VERSION ""

NS_ :

BS_:
BU_: Manager30 Battery_Sensor Redvision_1 Redvision_2 TVMS_Rouge TVMS_1280 Config_Tool

CM_ "Current/SOC decode v27. Long-log cleanup: source Manager30 and Battery Sensor currents are 32-bit little-endian values centred at exactly 1,000,000. Formula is raw/1000 - 1000. Redvision display copies are 16-bit values centred at exactly 10,000. Formula is raw/10 - 1000.";

CM_ BU_ Manager30 "Source address 0x01.";
CM_ BU_ Battery_Sensor "Source address 0x08.";
CM_ BU_ Redvision_1 "Source address 0x20.";
CM_ BU_ Redvision_2 "Source address 0x21.";

BO_ 2213677569 PGN_03F20A_Manager30_OutputCurrent: 8 Manager30
 SG_ Manager_Output_Current_A : 0|32@1+ (0.001,-1000) [-300|100] "A" Vector__XXX
 SG_ Manager_Battery_Voltage : 32|16@1+ (0.001,0) [0|20] "V" Vector__XXX

CM_ BO_ 2213677569 "Raw CAN ID 0x03F20A01, PGN 0x03F20A, SA 0x01 Manager30.";
CM_ SG_ 2213677569 Manager_Output_Current_A "Primary Manager30 output current. D1-D4 little-endian uint32. Clean formula: raw/1000 - 1000. Zero current raw = 1000000 = 0x000F4240, bytes 40 42 0F 00.";

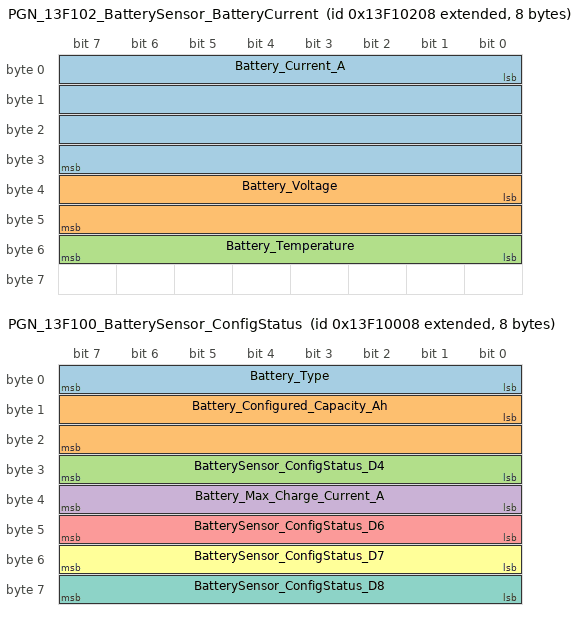
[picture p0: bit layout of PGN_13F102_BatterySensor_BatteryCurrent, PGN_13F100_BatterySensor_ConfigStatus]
BO_ 2482045448 PGN_13F102_BatterySensor_BatteryCurrent: 8 Battery_Sensor
 SG_ Battery_Current_A : 0|32@1+ (0.001,-1000) [-300|100] "A" Vector__XXX
 SG_ Battery_Voltage : 32|16@1+ (0.001,0) [0|20] "V" Vector__XXX
 SG_ Battery_Temperature : 48|8@1+ (1,-60) [-60|195] "degC" Vector__XXX

CM_ BO_ 2482045448 "Raw CAN ID 0x13F10208, PGN 0x13F102, SA 0x08 Battery_Sensor.";
CM_ SG_ 2482045448 Battery_Current_A "Primary battery current. D1-D4 little-endian uint32. Clean formula: raw/1000 - 1000. Positive = charging into batteries; negative = discharging from batteries. Zero current raw = 1000000 = 0x000F4240.";

BO_ 2482045960 PGN_13F104_BatterySensor_SOC: 8 Battery_Sensor
 SG_ Battery_SOC_Percent : 0|8@1+ (1,0) [0|100] "%" Vector__XXX

CM_ BO_ 2482045960 "Raw CAN ID 0x13F10408, PGN 0x13F104, SA 0x08 Battery_Sensor.";
CM_ SG_ 2482045960 Battery_SOC_Percent "Battery state of charge. D1 raw percent. Confirmed 99to97.csv: 0x63 -> 99%, 0x62 -> 98%, 0x61 -> 97%.";

BO_ 2482044936 PGN_13F100_BatterySensor_ConfigStatus: 8 Battery_Sensor
 SG_ Battery_Type : 0|8@1+ (1,0) [0|4] "type" Vector__XXX
 SG_ Battery_Configured_Capacity_Ah : 8|16@1+ (1,0) [0|1000] "Ah" Vector__XXX
 SG_ BatterySensor_ConfigStatus_D4 : 24|8@1+ (1,0) [0|255] "raw" Vector__XXX
 SG_ Battery_Max_Charge_Current_A : 32|8@1+ (1,0) [0|100] "A" Vector__XXX
 SG_ BatterySensor_ConfigStatus_D6 : 40|8@1+ (1,0) [0|255] "raw" Vector__XXX
 SG_ BatterySensor_ConfigStatus_D7 : 48|8@1+ (1,0) [0|255] "raw" Vector__XXX
 SG_ BatterySensor_ConfigStatus_D8 : 56|8@1+ (1,0) [0|255] "raw" Vector__XXX

CM_ BO_ 2482044936 "CONFIRMED_CORRECT_DO_NOT_EDIT: Battery Sensor config/status echo. Raw CAN ID 0x13F10008, private DGN 0x1F100, SA 0x08. D1 reports battery type, D2-D3 little-endian reports configured capacity Ah, D5 reports max charge current A.";
CM_ SG_ 2482044936 Battery_Type "D1 battery type. Confirmed from battery type change 5 times.csv: 0=Gel, 1=AGM, 2=LeadAcid, 3=Calcium, 4=Lithium.";
CM_ SG_ 2482044936 Battery_Configured_Capacity_Ah "D2-D3 little-endian unsigned Ah. Confirmed values: C2 01 = 450 Ah, 90 01 = 400 Ah, 5E 01 = 350 Ah.";
CM_ SG_ 2482044936 Battery_Max_Charge_Current_A "D5 raw amps. Confirmed from max charge current 20a - 15 - 20 -30.csv after correction: values follow 20 A, 14 A, 10 A, 30 A.";

BO_ 2399144186 BatterySensor_Config_Write_FromTool: 8 Config_Tool
 SG_ BatteryConfigWrite_Command M : 0|8@1+ (1,0) [0|255] "raw" Vector__XXX
 SG_ BatteryConfigWrite_D2 : 8|8@1+ (1,0) [0|255] "raw" Vector__XXX
 SG_ BatteryConfigWrite_Item : 16|8@1+ (1,0) [0|255] "raw" Vector__XXX
 SG_ BatteryConfigWrite_D4 : 24|8@1+ (1,0) [0|255] "raw" Vector__XXX
 SG_ BatteryConfigWrite_BatteryType m17 : 32|16@1+ (1,0) [0|4] "type" Vector__XXX
 SG_ BatteryConfigWrite_Capacity_Ah m18 : 32|16@1+ (1,0) [0|1000] "Ah" Vector__XXX
 SG_ BatteryConfigWrite_MaxChargeCurrent_A m20 : 32|16@1+ (1,0) [0|100] "A" Vector__XXX
 SG_ BatteryConfigWrite_SOCCalibrationTarget_Percent m21 : 32|16@1+ (1,0) [0|100] "%" Vector__XXX
 SG_ BatteryConfigWrite_LowSOCAlarm_Percent m65 : 32|16@1+ (1,0) [0|100] "%" Vector__XXX
 SG_ BatteryConfigWrite_LowVoltageAlarm_V m66 : 32|16@1+ (0.001,0) [0|60] "V" Vector__XXX
 SG_ BatteryConfigWrite_D7 : 48|8@1+ (1,0) [0|255] "raw" Vector__XXX
 SG_ BatteryConfigWrite_D8 : 56|8@1+ (1,0) [0|255] "raw" Vector__XXX

CM_ BO_ 2399144186 "CONFIRMED_CORRECT_DO_NOT_EDIT: Battery config write from source 0xFA to Battery_Sensor destination 0x08. Raw CAN ID 0x0F0008FA. D1 is command/mux; D1=0x11 writes battery type, D1=0x12 writes configured capacity Ah, D1=0x14 writes max charge current A, D1=0x15 calibrates/sets SOC target %, D1=0x41 writes low SOC alarm %, D1=0x42 writes low voltage alarm V.";
CM_ SG_ 2399144186 BatteryConfigWrite_Command "D1 command/mux. 0x11 = battery type, 0x12 = configured capacity, 0x14 = max charge current, 0x15 = SOC calibration target, 0x41 = low SOC alarm, 0x42 = low voltage alarm.";
CM_ SG_ 2399144186 BatteryConfigWrite_Item "D3 observed 0x03 for these battery config writes.";
CM_ SG_ 2399144186 BatteryConfigWrite_Capacity_Ah "D5-D6 little-endian unsigned Ah. Controlled sequence captured: 450 Ah, 400 Ah, 350 Ah, 400 Ah.";
CM_ SG_ 2399144186 BatteryConfigWrite_BatteryType "D5-D6 little-endian battery type. Confirmed from battery type change 5 times.csv sequence: 0=Gel, 1=AGM, 2=LeadAcid, 3=Calcium, 4=Lithium.";
CM_ SG_ 2399144186 BatteryConfigWrite_MaxChargeCurrent_A "D5-D6 little-endian unsigned A. Controlled sequence captured and corrected by user: 20 A, 14 A, 10 A, 30 A.";
CM_ SG_ 2399144186 BatteryConfigWrite_SOCCalibrationTarget_Percent "D5-D6 little-endian unsigned percent. calibrate battery start of charge full 5 times.csv captured five repeats of D1=0x15, D5-D6=0x0064, calibrating/setting battery SOC to 100%.";
CM_ SG_ 2399144186 BatteryConfigWrite_LowSOCAlarm_Percent "D5-D6 little-endian unsigned percent. Confirmed sequence from more battery config.csv: 10%, 15%, 20%, 30%.";
CM_ SG_ 2399144186 BatteryConfigWrite_LowVoltageAlarm_V "D5-D6 little-endian millivolts, scale 0.001 V/count. Confirmed sequence from more battery config.csv: 10.0 V, 11.0 V, 11.5 V, 12.0 V.";
VAL_ 2482044936 Battery_Type 0 "Gel" 1 "AGM" 2 "LeadAcid" 3 "Calcium" 4 "Lithium" ;
VAL_ 2399144186 BatteryConfigWrite_Command 17 "BatteryType" 18 "ConfiguredCapacity" 20 "MaxChargeCurrent" 21 "SOCCalibrationTarget" 65 "LowSOCAlarm" 66 "LowVoltageAlarm" ;
VAL_ 2399144186 BatteryConfigWrite_BatteryType 0 "Gel" 1 "AGM" 2 "LeadAcid" 3 "Calcium" 4 "Lithium" ;

BO_ 2399207200 Redvision1_Config_Setting_Broadcast: 8 Redvision_1
 SG_ RedvisionConfigBroadcast_Command M : 0|8@1+ (1,0) [0|255] "raw" Vector__XXX
 SG_ RedvisionConfigBroadcast_D2 : 8|8@1+ (1,0) [0|255] "raw" Vector__XXX
 SG_ RedvisionConfigBroadcast_D3 : 16|8@1+ (1,0) [0|255] "raw" Vector__XXX
 SG_ RedvisionConfigBroadcast_D4 : 24|8@1+ (1,0) [0|255] "raw" Vector__XXX
 SG_ RedvisionConfigBroadcast_BatteryType m17 : 32|16@1+ (1,0) [0|4] "type" Vector__XXX
 SG_ RedvisionConfigBroadcast_Capacity_Ah m18 : 32|16@1+ (1,0) [0|1000] "Ah" Vector__XXX
 SG_ RedvisionConfigBroadcast_MaxChargeCurrent_A m20 : 32|16@1+ (1,0) [0|100] "A" Vector__XXX
 SG_ RedvisionConfigBroadcast_LowSOCAlarm_Percent m65 : 32|16@1+ (1,0) [0|100] "%" Vector__XXX
 SG_ RedvisionConfigBroadcast_LowVoltageAlarm_V m66 : 32|16@1+ (0.001,0) [0|60] "V" Vector__XXX
 SG_ RedvisionConfigBroadcast_ChargingMode m67 : 32|8@1+ (1,0) [0|1] "mode" Vector__XXX
 SG_ RedvisionConfigBroadcast_ChargeCycleRequest_Candidate m77 : 32|8@1+ (1,0) [0|1] "request" Vector__XXX
 SG_ RedvisionConfigBroadcast_VehicleInputTrigger m104 : 32|16@1+ (1,0) [0|5] "trigger" Vector__XXX
 SG_ RedvisionConfigBroadcast_D7 : 48|8@1+ (1,0) [0|255] "raw" Vector__XXX
 SG_ RedvisionConfigBroadcast_D8 : 56|8@1+ (1,0) [0|255] "raw" Vector__XXX

CM_ BO_ 2399207200 "CONFIRMED_CORRECT_DO_NOT_EDIT: Redvision Display 1 local setting-change broadcast. Raw CAN ID 0x0F00FF20, source 0x20. Payload pattern <setting> 00 FF FF <value little-endian> 00 00. battery changes from redvision.csv shows the same setting IDs and value encoding as Bluetooth/config-tool changes.";
CM_ SG_ 2399207200 RedvisionConfigBroadcast_Command "D1 setting/mux. 0x11 = battery type, 0x12 = configured capacity, 0x14 = max charge current, 0x41 = low SOC alarm, 0x42 = low voltage alarm, 0x43 = Manager30 charging mode, 0x4D = charge-cycle/stage request candidate, 0x68 = vehicle input trigger.";
CM_ SG_ 2399207200 RedvisionConfigBroadcast_D3 "D3 observed 0xFF for these Redvision setting broadcasts.";
CM_ SG_ 2399207200 RedvisionConfigBroadcast_D4 "D4 observed 0xFF for these Redvision setting broadcasts.";
CM_ SG_ 2399207200 RedvisionConfigBroadcast_BatteryType "D5-D6 little-endian battery type. Confirmed examples: 2=LeadAcid, 0=Gel, 4=Lithium.";
CM_ SG_ 2399207200 RedvisionConfigBroadcast_Capacity_Ah "D5-D6 little-endian unsigned Ah. Confirmed examples: 0x0177=375 Ah, 0x0154=340 Ah, 0x0190=400 Ah.";
CM_ SG_ 2399207200 RedvisionConfigBroadcast_MaxChargeCurrent_A "D5-D6 little-endian unsigned A. Confirmed example: 0x001E=30 A.";
CM_ SG_ 2399207200 RedvisionConfigBroadcast_LowSOCAlarm_Percent "D5-D6 little-endian unsigned percent. Confirmed example: 0x001E=30%.";
CM_ SG_ 2399207200 RedvisionConfigBroadcast_LowVoltageAlarm_V "D5-D6 little-endian millivolts, scale 0.001 V/count. Confirmed example: 0x2EE0=12.0 V.";
CM_ SG_ 2399207200 RedvisionConfigBroadcast_ChargingMode "CONFIRMED_CORRECT_DO_NOT_EDIT: D1=0x43 Manager30 charging mode command. D5=0x00 Touring, D5=0x01 Storage. Observed RedVision source 0x20 sends 43 00 FF FF <mode> 00 00 00.";
CM_ SG_ 2399207200 RedvisionConfigBroadcast_ChargeCycleRequest_Candidate "PARTLY_CONFIRMED: D1=0x4D charge-cycle/stage request candidate. Observed 4D 00 FF FF 01 00 00 00 before later Float->Boost transition, but it did not immediately change live stage status.";
CM_ SG_ 2399207200 RedvisionConfigBroadcast_VehicleInputTrigger "D5-D6 little-endian trigger value. Confirmed examples: 0=Auto, 1=12V, 3=Ignition.";
CM_ SG_ 2399207200 RedvisionConfigBroadcast_D7 "D7 observed 0x00 for these Redvision setting broadcasts.";
CM_ SG_ 2399207200 RedvisionConfigBroadcast_D8 "D8 observed 0x00 for these Redvision setting broadcasts.";
VAL_ 2399207200 RedvisionConfigBroadcast_Command 17 "BatteryType" 18 "ConfiguredCapacity" 20 "MaxChargeCurrent" 65 "LowSOCAlarm" 66 "LowVoltageAlarm" 67 "ChargingMode" 77 "ChargeCycleRequest_Candidate" 104 "VehicleInputTrigger" ;
VAL_ 2399207200 RedvisionConfigBroadcast_BatteryType 0 "Gel" 1 "AGM" 2 "LeadAcid" 3 "Calcium" 4 "Lithium" ;
VAL_ 2399207200 RedvisionConfigBroadcast_ChargingMode 0 "Touring" 1 "Storage" ;
VAL_ 2399207200 RedvisionConfigBroadcast_ChargeCycleRequest_Candidate 1 "RequestBoostOrRestartCycle" ;
VAL_ 2399207200 RedvisionConfigBroadcast_VehicleInputTrigger 0 "Auto" 1 "12V" 2 "24V" 3 "Ignition" 5 "On" ;

BO_ 2482143264 PGN_13F280_Redvision1_CurrentDisplay: 8 Redvision_1
 SG_ RV1_Battery_Current_Display_A : 0|16@1+ (0.1,-1000) [-300|100] "A" Vector__XXX
 SG_ RV1_Device_Current_Display_A : 32|16@1+ (0.1,-1000) [0|300] "A" Vector__XXX

CM_ BO_ 2482143264 "Raw CAN ID 0x13F28020, PGN 0x13F280, SA 0x20 Redvision_1. Redvision display/rebroadcast current values.";
CM_ SG_ 2482143264 RV1_Battery_Current_Display_A "Redvision_1 displayed battery current. D1-D2 little-endian uint16. Clean formula: raw/10 - 1000. Zero current raw = 10000 = 0x2710.";
CM_ SG_ 2482143264 RV1_Device_Current_Display_A "Redvision_1 displayed device/load current. D5-D6 little-endian uint16. Clean formula: raw/10 - 1000. Zero current raw = 10000 = 0x2710.";

BO_ 2482143777 PGN_13F282_Redvision2_CurrentDisplay: 8 Redvision_2
 SG_ RV2_Manager_Output_Current_Display_A : 48|16@1+ (0.1,-1000) [-50|100] "A" Vector__XXX

CM_ BO_ 2482143777 "Raw CAN ID 0x13F28221, PGN 0x13F282, SA 0x21 Redvision_2. Redvision display/rebroadcast Manager30 output current.";
CM_ SG_ 2482143777 RV2_Manager_Output_Current_Display_A "Redvision_2 displayed Manager30 output current. D7-D8 little-endian uint16. Clean formula: raw/10 - 1000. Zero current raw = 10000 = 0x2710.";

CM_ "Derived source-node device/load current: Device_Current_A = Manager_Output_Current_A - Battery_Current_A.";
CM_ "Battery_Current_A sign convention: positive means charging into batteries; negative means battery discharge.";
CM_ "Long-log validation: Manager30 0x03F20A01 D1-D4 raw 0x000F4240 decodes 0 A; raw around 1030700 decodes about 30.7 A.";
CM_ "Long-log validation: Battery Sensor 0x13F10208 D1-D4 decodes from about -212 A to +30 A and tracks Redvision_1 battery display.";
CM_ "Redvision validation: display currents remain centred on 10000 with 0.1 A/count.";

BO_ 2617049648 PGN_1BFD02_TVMSRouge_WaterTankLevels: 8 TVMS_Rouge
 SG_ WaterTank_MUX M : 0|8@1+ (1,0) [0|255] "" Vector__XXX
 SG_ WaterTank1_Percent m9 : 8|8@1+ (1,0) [0|100] "%" Vector__XXX
 SG_ WaterTank2_Percent m9 : 16|8@1+ (1,0) [0|100] "%" Vector__XXX
 SG_ TVMSRouge_Input_Voltage m22 : 8|16@1+ (0.001,0) [0|65.535] "V" Vector__XXX
 SG_ TVMSRouge_Input_Current_A_Candidate m22 : 16|8@1+ (0.1,0) [0|25.5] "A" Vector__XXX

CM_ BO_ 2617049648 "Confirmed TVMS_Rouge water tank levels. Raw CAN ID 0x1BFD0230, PGN 0xFD02, source address 0x30.";
CM_ SG_ 2617049648 WaterTank_MUX "D1 message type/mux. 0x09 = water tank levels. 0x16 = live input voltage and current.";
CM_ SG_ 2617049648 WaterTank1_Percent "D2 = Tank 1 level percent. 0x00 = 0%, 0x64 = 100%. Scale: raw percent.";
CM_ SG_ 2617049648 WaterTank2_Percent "D3 = Tank 2 level percent. 0x00 = 0%, 0x64 = 100%. Scale: raw percent.";
CM_ SG_ 2617049648 TVMSRouge_Input_Voltage "CONFIRMED_CORRECT_DO_NOT_EDIT: MUX 0x16, D2-D3 little-endian uint16 millivolts. Live input voltage. ESPHome: data[1]|(data[2]<<8) / 1000.0.";
CM_ SG_ 2617049648 TVMSRouge_Input_Current_A_Candidate "DECODE_WRONG_PENDING_RETEST: Label pages identify item 0x17 as Input Current, but 0x1BFD0230 D1=0x16 D3 is the high byte of the confirmed D2-D3 input-voltage millivolt field. Do not publish D3/10 A as current. Find the real current page, likely item/mux 0x17 or another frame, with controlled load-current testing.";
VAL_ 2617049648 WaterTank_MUX 9 "WaterTankLevels" 22 "InputVoltageCurrentCandidates";

CM_

BA_ "Decode_Status"

CM_ "v30 update: added confirmed TVMS_1280 Tank1 level on 0x1BFD0224 MUX 0x14 D4, raw percent.";

CM_ "v31 TVMS1280 water 1-6 review: only one clean raw 25%/0% tank-level field was found in the uploaded log: raw CAN ID 0x1BFD0224, MUX 0x14, D4 = TVMS1280_Tank1_Percent. No separate confirmed 25/0 raw percent fields for TVMS1280 tanks 2-6 were visible in this capture, so they were not added as confirmed signals.";
CM_ "TVMS1280 Tank1 validation from TVMS1280 water 1-6.csv: log starts with Tank1 at 25%, later D4 changes to 0%, and ends with Tank1 back at 25%.";

CM_ "v32 TVMS1280 Tank2 review: 1280 tank 2 100-0.csv was inspected. No source address 0x24 field showed a clean 100% to 0% raw-percent change, so TVMS1280_Tank2_Percent was not added as a confirmed signal.";
CM_ "v32 observed 0x24 frames: 0x1BFD0224 cycles mux 0x11/0x14/0x17/0x1A; mux 0x14 D4, previously confirmed Tank1, remained 0 in this capture. 0x1BFD0024 and other source 0x24 frames were static/status-like and did not carry a 100 to 0 percent value.";

CM_

BA_ "Decode_Status"

CM_ "v33 update: TVMS1280 Tank2 confirmed on raw CAN ID 0x1BFD0224, mux 0x14, D6, raw percent.";

CM_
 0x00=0%, 0x64=100%.";

BA_ "Decode_Status" 


CM_ "v35 update: mux 0x1A D2 renamed from TVMS1280_Tank5_Percent to TVMS1280_Tank6_Percent per confirmed physical mapping.";
CM_ "v53 update: Added TVMS Rouge Input Current candidate. Superseded by later review: D3 in 0x1BFD0230 D1=0x16 belongs to the confirmed D2-D3 voltage field, so D3/10 A must not be used as current.";

BO_ 2617049636 PGN_1BFD02_TVMS1280_TempTankStatus: 8 TVMS_1280
 SG_ TVMS1280_Status_MUX M : 0|8@1+ (1,0) [0|255] "" Vector__XXX
 SG_ TVMS1280_Temp1_C m20 : 8|8@1+ (1,-100) [-100|155] "degC" Vector__XXX
 SG_ TVMS1280_Tank1_Percent m20 : 24|8@1+ (1,0) [0|100] "%" Vector__XXX
 SG_ TVMS1280_Tank2_Percent m20 : 40|8@1+ (1,0) [0|100] "%" Vector__XXX
 SG_ TVMS1280_Tank3_Percent m23 : 8|8@1+ (1,0) [0|100] "%" Vector__XXX
 SG_ TVMS1280_Tank4_Percent m23 : 24|8@1+ (1,0) [0|100] "%" Vector__XXX
 SG_ TVMS1280_Tank5_Percent m23 : 40|8@1+ (1,0) [0|100] "%" Vector__XXX
 SG_ TVMS1280_Tank6_Percent m26 : 8|8@1+ (1,0) [0|100] "%" Vector__XXX
 SG_ TVMS1280_Temp2_C m17 : 40|8@1+ (1,-100) [-100|155] "degC" Vector__XXX
 SG_ TVMS1280_Voltage_Input1 m17 : 8|16@1+ (0.001,0) [0|65.535] "V" Vector__XXX
 SG_ TVMS1280_Voltage_Input2 m17 : 24|16@1+ (0.001,0) [0|65.535] "V" Vector__XXX

CM_ BO_ 2617049636 "Confirmed TVMS_1280 temp/tank status. Raw CAN ID 0x1BFD0224, PGN 0xFD02, source address 0x24. Also a candidate frame to watch for the 3 currently unused TVMS1280 digital inputs, but no digital-input decode is confirmed.";
CM_ SG_ 2617049636 TVMS1280_Status_MUX "D1 multiplexor. 0x11 contains Voltage Input 1, Voltage Input 2 and Temp2. 0x14 contains Temp1, Tank1 and Tank2. 0x17 contains Tank3, Tank4 and Tank5. 0x1A contains Tank6.";
CM_ SG_ 2617049636 TVMS1280_Temp1_C "MUX 0x14, D2. Temperature formula raw - 100.";
CM_ SG_ 2617049636 TVMS1280_Tank1_Percent "MUX 0x14, D4. Raw percent.";
CM_ SG_ 2617049636 TVMS1280_Tank2_Percent "MUX 0x14, D6. Raw percent.";
CM_ SG_ 2617049636 TVMS1280_Tank3_Percent "MUX 0x17, D2. Raw percent.";
CM_ SG_ 2617049636 TVMS1280_Tank4_Percent "MUX 0x17, D4. Raw percent.";
CM_ SG_ 2617049636 TVMS1280_Tank5_Percent "CONFIRMED_CORRECT_DO_NOT_EDIT: MUX 0x17, D6. Confirmed TVMS1280 Tank 5 percent. Raw value is percent; 0x00=0%, 0x64=100%.";
CM_ SG_ 2617049636 TVMS1280_Tank6_Percent "MUX 0x1A, D2. Raw percent.";
CM_ SG_ 2617049636 TVMS1280_Temp2_C "MUX 0x11, D6. Temperature formula raw - 100.";
CM_ SG_ 2617049636 TVMS1280_Voltage_Input1 "CONFIRMED_CORRECT_DO_NOT_EDIT: MUX 0x11, D2-D3 little-endian uint16 millivolts. Voltage Input 1. Confirmed ~13581-13588 mV (~13.5 V) within 0.1 V of Voltage Input 2 in voltage inputs the same.csv capture. ESPHome: data[1]|(data[2]<<8) / 1000.0.";
CM_ SG_ 2617049636 TVMS1280_Voltage_Input2 "CONFIRMED_CORRECT_DO_NOT_EDIT: MUX 0x11, D4-D5 little-endian uint16 millivolts. Voltage Input 2 (same signal as supply voltage). Confirmed ~13531-13536 mV (~13.5 V) in voltage input 1280 555 36.csv capture. ESPHome: data[3]|(data[4]<<8) / 1000.0.";
VAL_ 2617049636 TVMS1280_Status_MUX 17 "Temp2_SupplyVoltage" 20 "Temp1_Tank1_Tank2" 23 "Tank3_Tank4_Tank5" 26 "Tank6";


CM_ "v36 update: TVMS1280 Tank5 confirmed on raw CAN ID 0x1BFD0224, mux 0x17, D6. Tank5 uses scale 1.25 because 0x50 represents 100% in the tank 5 100-0.csv capture.";

BA_DEF_ BO_ "Decode_Status" STRING ;
BA_DEF_ SG_ "Decode_Status" STRING ;
BA_DEF_DEF_ "Decode_Status" "CONFIRMED_CORRECT_DO_NOT_EDIT";
CM_ "LOCKED_CONFIRMED_DECODE: Every message and signal in this DBC is marked CONFIRMED_CORRECT_DO_NOT_EDIT per user request. Do not change these values unless the user explicitly requests a correction.";
BA_ "Decode_Status" BO_ 2213677569 "CONFIRMED_CORRECT_DO_NOT_EDIT";
BA_ "Decode_Status" SG_ 2213677569 Manager_Output_Current_A "CONFIRMED_CORRECT_DO_NOT_EDIT";
BA_ "Decode_Status" BO_ 2482045448 "CONFIRMED_CORRECT_DO_NOT_EDIT";
BA_ "Decode_Status" SG_ 2482045448 Battery_Current_A "CONFIRMED_CORRECT_DO_NOT_EDIT";
BA_ "Decode_Status" BO_ 2482045960 "CONFIRMED_CORRECT_DO_NOT_EDIT";
BA_ "Decode_Status" SG_ 2482045960 Battery_SOC_Percent "CONFIRMED_CORRECT_DO_NOT_EDIT";
BA_ "Decode_Status" BO_ 2482044936 "CONFIRMED_CORRECT_DO_NOT_EDIT";
BA_ "Decode_Status" SG_ 2482044936 Battery_Type "CONFIRMED_CORRECT_DO_NOT_EDIT";
BA_ "Decode_Status" SG_ 2482044936 Battery_Configured_Capacity_Ah "CONFIRMED_CORRECT_DO_NOT_EDIT";
BA_ "Decode_Status" SG_ 2482044936 BatterySensor_ConfigStatus_D4 "UNCONFIRMED_PENDING_TEST";
BA_ "Decode_Status" SG_ 2482044936 Battery_Max_Charge_Current_A "CONFIRMED_CORRECT_DO_NOT_EDIT";
BA_ "Decode_Status" SG_ 2482044936 BatterySensor_ConfigStatus_D6 "UNCONFIRMED_PENDING_TEST";
BA_ "Decode_Status" SG_ 2482044936 BatterySensor_ConfigStatus_D7 "UNCONFIRMED_PENDING_TEST";
BA_ "Decode_Status" SG_ 2482044936 BatterySensor_ConfigStatus_D8 "UNCONFIRMED_PENDING_TEST";
BA_ "Decode_Status" BO_ 2399144186 "CONFIRMED_CORRECT_DO_NOT_EDIT";
BA_ "Decode_Status" SG_ 2399144186 BatteryConfigWrite_Command "CONFIRMED_CORRECT_DO_NOT_EDIT";
BA_ "Decode_Status" SG_ 2399144186 BatteryConfigWrite_D2 "UNCONFIRMED_PENDING_TEST";
BA_ "Decode_Status" SG_ 2399144186 BatteryConfigWrite_Item "CONFIRMED_CORRECT_DO_NOT_EDIT";
BA_ "Decode_Status" SG_ 2399144186 BatteryConfigWrite_D4 "UNCONFIRMED_PENDING_TEST";
BA_ "Decode_Status" SG_ 2399144186 BatteryConfigWrite_BatteryType "CONFIRMED_CORRECT_DO_NOT_EDIT";
BA_ "Decode_Status" SG_ 2399144186 BatteryConfigWrite_Capacity_Ah "CONFIRMED_CORRECT_DO_NOT_EDIT";
BA_ "Decode_Status" SG_ 2399144186 BatteryConfigWrite_MaxChargeCurrent_A "CONFIRMED_CORRECT_DO_NOT_EDIT";
BA_ "Decode_Status" SG_ 2399144186 BatteryConfigWrite_SOCCalibrationTarget_Percent "CONFIRMED_CORRECT_DO_NOT_EDIT";
BA_ "Decode_Status" SG_ 2399144186 BatteryConfigWrite_LowSOCAlarm_Percent "CONFIRMED_CORRECT_DO_NOT_EDIT";
BA_ "Decode_Status" SG_ 2399144186 BatteryConfigWrite_LowVoltageAlarm_V "CONFIRMED_CORRECT_DO_NOT_EDIT";
BA_ "Decode_Status" SG_ 2399144186 BatteryConfigWrite_D7 "UNCONFIRMED_PENDING_TEST";
BA_ "Decode_Status" SG_ 2399144186 BatteryConfigWrite_D8 "UNCONFIRMED_PENDING_TEST";
BA_ "Decode_Status" BO_ 2399207200 "CONFIRMED_CORRECT_DO_NOT_EDIT";
BA_ "Decode_Status" SG_ 2399207200 RedvisionConfigBroadcast_Command "CONFIRMED_CORRECT_DO_NOT_EDIT";
BA_ "Decode_Status" SG_ 2399207200 RedvisionConfigBroadcast_D2 "UNCONFIRMED_PENDING_TEST";
BA_ "Decode_Status" SG_ 2399207200 RedvisionConfigBroadcast_D3 "CONFIRMED_CORRECT_DO_NOT_EDIT";
BA_ "Decode_Status" SG_ 2399207200 RedvisionConfigBroadcast_D4 "CONFIRMED_CORRECT_DO_NOT_EDIT";
BA_ "Decode_Status" SG_ 2399207200 RedvisionConfigBroadcast_BatteryType "CONFIRMED_CORRECT_DO_NOT_EDIT";
BA_ "Decode_Status" SG_ 2399207200 RedvisionConfigBroadcast_Capacity_Ah "CONFIRMED_CORRECT_DO_NOT_EDIT";
BA_ "Decode_Status" SG_ 2399207200 RedvisionConfigBroadcast_MaxChargeCurrent_A "CONFIRMED_CORRECT_DO_NOT_EDIT";
BA_ "Decode_Status" SG_ 2399207200 RedvisionConfigBroadcast_LowSOCAlarm_Percent "CONFIRMED_CORRECT_DO_NOT_EDIT";
BA_ "Decode_Status" SG_ 2399207200 RedvisionConfigBroadcast_LowVoltageAlarm_V "CONFIRMED_CORRECT_DO_NOT_EDIT";
BA_ "Decode_Status" SG_ 2399207200 RedvisionConfigBroadcast_ChargingMode "CONFIRMED_CORRECT_DO_NOT_EDIT";
BA_ "Decode_Status" SG_ 2399207200 RedvisionConfigBroadcast_ChargeCycleRequest_Candidate "PARTLY_CONFIRMED";
BA_ "Decode_Status" SG_ 2399207200 RedvisionConfigBroadcast_VehicleInputTrigger "CONFIRMED_CORRECT_DO_NOT_EDIT";
BA_ "Decode_Status" SG_ 2399207200 RedvisionConfigBroadcast_D7 "CONFIRMED_CORRECT_DO_NOT_EDIT";
BA_ "Decode_Status" SG_ 2399207200 RedvisionConfigBroadcast_D8 "CONFIRMED_CORRECT_DO_NOT_EDIT";
BA_ "Decode_Status" BO_ 2482143264 "CONFIRMED_CORRECT_DO_NOT_EDIT";
BA_ "Decode_Status" SG_ 2482143264 RV1_Battery_Current_Display_A "CONFIRMED_CORRECT_DO_NOT_EDIT";
BA_ "Decode_Status" SG_ 2482143264 RV1_Device_Current_Display_A "CONFIRMED_CORRECT_DO_NOT_EDIT";
BA_ "Decode_Status" BO_ 2482143777 "CONFIRMED_CORRECT_DO_NOT_EDIT";
BA_ "Decode_Status" SG_ 2482143777 RV2_Manager_Output_Current_Display_A "CONFIRMED_CORRECT_DO_NOT_EDIT";
BA_ "Decode_Status" BO_ 2617049648 "CONFIRMED_CORRECT_DO_NOT_EDIT";
BA_ "Decode_Status" SG_ 2617049648 WaterTank_MUX "CONFIRMED_CORRECT_DO_NOT_EDIT";
BA_ "Decode_Status" SG_ 2617049648 WaterTank1_Percent "CONFIRMED_CORRECT_DO_NOT_EDIT";
BA_ "Decode_Status" SG_ 2617049648 WaterTank2_Percent "CONFIRMED_CORRECT_DO_NOT_EDIT";
BA_ "Decode_Status" SG_ 2617049648 TVMSRouge_Input_Voltage "CONFIRMED_CORRECT_DO_NOT_EDIT";
BA_ "Decode_Status" SG_ 2617049648 TVMSRouge_Input_Current_A_Candidate "UNCONFIRMED_PENDING_TEST";
BA_ "Decode_Status" BO_ 2617049636 "CONFIRMED_CORRECT_DO_NOT_EDIT";
BA_ "Decode_Status" SG_ 2617049636 TVMS1280_Status_MUX "CONFIRMED_CORRECT_DO_NOT_EDIT";
BA_ "Decode_Status" SG_ 2617049636 TVMS1280_Temp1_C "CONFIRMED_CORRECT_DO_NOT_EDIT";
BA_ "Decode_Status" SG_ 2617049636 TVMS1280_Tank1_Percent "CONFIRMED_CORRECT_DO_NOT_EDIT";
BA_ "Decode_Status" SG_ 2617049636 TVMS1280_Tank2_Percent "CONFIRMED_CORRECT_DO_NOT_EDIT";
BA_ "Decode_Status" SG_ 2617049636 TVMS1280_Tank3_Percent "CONFIRMED_CORRECT_DO_NOT_EDIT";
BA_ "Decode_Status" SG_ 2617049636 TVMS1280_Tank4_Percent "CONFIRMED_CORRECT_DO_NOT_EDIT";
BA_ "Decode_Status" SG_ 2617049636 TVMS1280_Tank5_Percent "CONFIRMED_CORRECT_DO_NOT_EDIT";
BA_ "Decode_Status" SG_ 2617049636 TVMS1280_Tank6_Percent "CONFIRMED_CORRECT_DO_NOT_EDIT";
BA_ "Decode_Status" SG_ 2617049636 TVMS1280_Temp2_C "CONFIRMED_CORRECT_DO_NOT_EDIT";
BA_ "Decode_Status" SG_ 2617049636 TVMS1280_Voltage_Input1 "CONFIRMED_CORRECT_DO_NOT_EDIT";
BA_ "Decode_Status" SG_ 2617049636 TVMS1280_Voltage_Input2 "CONFIRMED_CORRECT_DO_NOT_EDIT";

CM_ SG_ 2213677569 Manager_Battery_Voltage "CONFIRMED_CORRECT_DO_NOT_EDIT: Manager30 battery voltage confirmed. Raw CAN ID 0x03F20A01, D5-D6 little-endian, scale 0.001 V/count.";
BA_ "Decode_Status" SG_ 2213677569 Manager_Battery_Voltage "CONFIRMED_CORRECT_DO_NOT_EDIT";

CM_ SG_ 2482045448 Battery_Voltage "CONFIRMED_CORRECT_DO_NOT_EDIT: Battery Sensor voltage confirmed. Raw CAN ID 0x13F10208, D5-D6 little-endian, scale 0.001 V/count.";
BA_ "Decode_Status" SG_ 2482045448 Battery_Voltage "CONFIRMED_CORRECT_DO_NOT_EDIT";

BO_ 2213676033 PGN_03F204_Manager30_AC_DC_Voltage_Candidates: 8 Manager30
 SG_ AC_Input_Voltage : 32|16@1+ (1,0) [0|300] "V" Vector__XXX
 SG_ DC_Input_Voltage_Raw : 48|16@1- (1,0) [-32768|32767] "raw" Vector__XXX
CM_ BO_ 2213676033 "UNCONFIRMED_PENDING_TEST: imported voltage candidates from older DBC. Raw CAN ID 0x03F20401.";
CM_ SG_ 2213676033 AC_Input_Voltage "CONFIRMED_CORRECT_DO_NOT_EDIT: AC input voltage confirmed. Raw CAN ID 0x03F20401, D5-D6 little-endian, scale 1 V/count.";
CM_ SG_ 2213676033 DC_Input_Voltage_Raw "UNCONFIRMED_PENDING_TEST: candidate DC input voltage/raw field, D7-D8 signed little-endian. Final voltage scale not confirmed.";
BA_ "Decode_Status" BO_ 2213676033 "UNCONFIRMED_PENDING_TEST";
BA_ "Decode_Status" SG_ 2213676033 AC_Input_Voltage "CONFIRMED_CORRECT_DO_NOT_EDIT";
BA_ "Decode_Status" SG_ 2213676033 DC_Input_Voltage_Raw "UNCONFIRMED_PENDING_TEST";


CM_ 

BA_ "Decode_Status" 


CM_ "v38 update: merged voltage candidates from TVMS_Redvision_v6_amp_calibrated(1).dbc into the latest confirmed DBC. Added voltage candidates are marked UNCONFIRMED_PENDING_TEST; previously confirmed current/SOC/tank signals remain CONFIRMED_CORRECT_DO_NOT_EDIT.";

CM_ SG_ 2482045448 Battery_Temperature "CONFIRMED_CORRECT_DO_NOT_EDIT: Battery Sensor temperature confirmed. Raw CAN ID 0x13F10208, D7, formula raw - 60 degC.";
BA_ "Decode_Status" SG_ 2482045448 Battery_Temperature "CONFIRMED_CORRECT_DO_NOT_EDIT";
CM_ "v39 update: merged Battery_Temperature candidate from TVMS_Redvision_v6_amp_calibrated(1).dbc. It is marked UNCONFIRMED_PENDING_TEST; existing confirmed signals remain CONFIRMED_CORRECT_DO_NOT_EDIT.";

CM_ "v40 update: Battery Sensor voltage and Battery Sensor temperature marked CONFIRMED_CORRECT_DO_NOT_EDIT. Other voltage candidates remain UNCONFIRMED_PENDING_TEST.";

CM_ "v41 update: AC_Input_Voltage marked CONFIRMED_CORRECT_DO_NOT_EDIT. Other unconfirmed voltage candidates remain UNCONFIRMED_PENDING_TEST.";

CM_ "v42 update: Manager_Battery_Voltage marked CONFIRMED_CORRECT_DO_NOT_EDIT. DC_Input_Voltage_Raw and Solar_Input_Voltage remain UNCONFIRMED_PENDING_TEST.";

CM_ "v43 update: Solar_Input_Voltage scale changed to 0.01 V/count, bias 0. It remains UNCONFIRMED_PENDING_TEST until confirmed after testing.";

CM_ "v44 update: Solar_Input_Voltage scale changed to 0.001 V/count, bias 0. It remains UNCONFIRMED_PENDING_TEST until confirmed after testing.";


CM_ 

CM_ "v45 update: Solar wattage is derived from Manager30 0x03F20801 as Solar_Input_Current_A * Solar_Input_Voltage. In solar 80-70 log this gives about 81 W at start, varies up/down, and averages about 75 W. DBC cannot encode multiplication directly, so current and voltage are added as separate unconfirmed test signals.";
BA_ "Decode_Status" 


BO_ 2214385153 PGN_03FCD6_Manager30_SolarEnergy: 8 Manager30
 SG_ Solar_Energy_Page : 0|8@1+ (1,0) [0|255] "page" Vector__XXX
 SG_ Solar_Energy_Wh : 8|32@1+ (1,0) [0|4294967295] "Wh" Vector__XXX

CM_ BO_ 2214385153 "CONFIRMED_CORRECT_DO_NOT_EDIT: Manager30 solar energy/yield. Raw CAN ID 0x03FCD601, PGN 0x03FCD6, SA 0x01. Decode only page D1=0x00.";
CM_ SG_ 2214385153 Solar_Energy_Page "D1 page/index. 0x00 contains Solar_Energy_Wh. Companion pages 0x01 and 0x02 were observed but remain unknown/ignored.";
CM_ SG_ 2214385153 Solar_Energy_Wh "CONFIRMED_CORRECT_DO_NOT_EDIT: D2-D5 little-endian uint32, scale 1 Wh/count. solar wh 14-19 log shows 0x0000000E to 0x00000013 while displayed solar Wh went 14 to 19.";
VAL_ 2214385153 Solar_Energy_Page 0 "SolarEnergyWh" 1 "Page1_Unknown" 2 "Page2_Unknown";
BA_ "Decode_Status" BO_ 2214385153 "CONFIRMED_CORRECT_DO_NOT_EDIT";
BA_ "Decode_Status" SG_ 2214385153 Solar_Energy_Page "CONFIRMED_CORRECT_DO_NOT_EDIT";
BA_ "Decode_Status" SG_ 2214385153 Solar_Energy_Wh "CONFIRMED_CORRECT_DO_NOT_EDIT";

CM_ "v46 update: added Manager30 Solar_Energy_Wh candidate from 0x03FCD601 D1=0x00 D2-D3. The test log shows 14 Wh to 19 Wh. Marked UNCONFIRMED_PENDING_TEST until user confirms.";

BO_ 2213677057 PGN_03F208_Manager30_SolarInput: 8 Manager30
 SG_ Solar_Input_Power_W_Est : 0|32@1+ (0.022,-22000) [-3000|3000] "W" Vector__XXX
 SG_ Solar_Input_Voltage : 32|16@1+ (0.001,0) [0|80] "V" Vector__XXX

CM_ BO_ 2213677057 "UNCONFIRMED_PENDING_TEST: Manager30 solar input fields. Raw CAN ID 0x03F20801.";
CM_ SG_ 2213677057 Solar_Input_Power_W_Est "UNCONFIRMED_PENDING_TEST: solar watts estimate converted from the former Solar_Input_Current_A using nominal 22 V. Formula in DBC: raw*0.022 - 22000 W. Exact solar watts require multiplying live current by live voltage in software.";
CM_ SG_ 2213677057 Solar_Input_Voltage "UNCONFIRMED_PENDING_TEST: candidate solar input voltage. D5-D6 little-endian, formula raw*0.001 V.";
CM_ "v48 update: Solar_Input_Current_A was converted to Solar_Input_Power_W_Est in the DBC using nominal 22 V. Standard DBC cannot calculate live Solar_Input_Current_A x Solar_Input_Voltage, so this is an estimate. Use ESPHome/Home Assistant for exact live watts.";
BA_ "Decode_Status" BO_ 2213677057 "UNCONFIRMED_PENDING_TEST";
BA_ "Decode_Status" SG_ 2213677057 Solar_Input_Power_W_Est "UNCONFIRMED_PENDING_TEST";
BA_ "Decode_Status" SG_ 2213677057 Solar_Input_Voltage "UNCONFIRMED_PENDING_TEST";

BO_ 2213741569 PGN_03F304_Manager30_Clock: 8 Manager30
 SG_ Manager30_Clock_Flags_Raw : 0|3@1+ (1,0) [0|7] "raw" Vector__XXX
 SG_ Manager30_Clock_Day_Of_Month : 3|5@1+ (1,1) [1|31] "day" Vector__XXX
 SG_ Manager30_Clock_Month : 8|8@1+ (1,0) [1|12] "month" Vector__XXX
 SG_ Manager30_Clock_Year : 16|16@1+ (1,0) [2000|2100] "year" Vector__XXX
 SG_ Manager30_Clock_Hour : 32|8@1+ (1,0) [0|23] "hour" Vector__XXX
 SG_ Manager30_Clock_Minute : 40|8@1+ (1,0) [0|59] "minute" Vector__XXX
 SG_ Manager30_Clock_Second : 48|8@1+ (1,0) [0|59] "second" Vector__XXX
 SG_ Manager30_Clock_Pad : 56|8@1+ (1,0) [0|255] "raw" Vector__XXX
CM_ BO_ 2213741569 "PARTLY_CONFIRMED: Manager30 clock/time frame. Raw CAN ID 0x03F30401, PGN 0x03F304, SA 0x01. Observed payload 9E 06 EA 07 0B 29 08 FF decodes as 2026-06-20 11:41:08 and C4 06 EA 07 0B 2F 19 FF decodes as 2026-06-25 11:47:25 using day = (D1 >> 3) + 1. D8 is padding.";
CM_ SG_ 2213741569 Manager30_Clock_Flags_Raw "UNCONFIRMED_PENDING_TEST: D1 low 3 bits. Examples: 0x9E & 0x07 = 6, 0xC4 & 0x07 = 4.";
CM_ SG_ 2213741569 Manager30_Clock_Day_Of_Month "PARTLY_CONFIRMED: D1 high 5 bits plus 1 gives day-of-month. Examples: 0x9E >> 3 = 19, +1 = 20; 0xC4 >> 3 = 24, +1 = 25.";
CM_ SG_ 2213741569 Manager30_Clock_Month "PARTLY_CONFIRMED: D2 month number. Observed 0x06 in June captures.";
CM_ SG_ 2213741569 Manager30_Clock_Year "PARTLY_CONFIRMED: D3-D4 little-endian year. Observed EA 07 = 2026.";
CM_ SG_ 2213741569 Manager30_Clock_Hour "PARTLY_CONFIRMED: D5 hour, 24-hour clock. Observed 0x0D = 13 in 1:48 PM capture.";
CM_ SG_ 2213741569 Manager30_Clock_Minute "PARTLY_CONFIRMED: D6 minute. Observed 0x30 = 48 in 1:48 PM capture.";
CM_ SG_ 2213741569 Manager30_Clock_Second "PARTLY_CONFIRMED: D7 second; increments once per second in find unknown.csv.";
BA_ "Decode_Status" BO_ 2213741569 "PARTLY_CONFIRMED";
BA_ "Decode_Status" SG_ 2213741569 Manager30_Clock_Day_Of_Month "PARTLY_CONFIRMED";
BA_ "Decode_Status" SG_ 2213741569 Manager30_Clock_Flags_Raw "UNCONFIRMED_PENDING_TEST";
BA_ "Decode_Status" SG_ 2213741569 Manager30_Clock_Month "PARTLY_CONFIRMED";
BA_ "Decode_Status" SG_ 2213741569 Manager30_Clock_Year "PARTLY_CONFIRMED";
BA_ "Decode_Status" SG_ 2213741569 Manager30_Clock_Hour "PARTLY_CONFIRMED";
BA_ "Decode_Status" SG_ 2213741569 Manager30_Clock_Minute "PARTLY_CONFIRMED";
BA_ "Decode_Status" SG_ 2213741569 Manager30_Clock_Second "PARTLY_CONFIRMED";

CM_ "v55 update: Added Manager30 clock candidate on raw CAN ID 0x03F30401. Month/year/hour/minute/second are partly confirmed from find unknown.csv; D1 high 5 bits plus 1 gives day-of-month, low 3 bits remain unknown flags.";

BO_ 66127873 PGN_03F108_Manager30_Status: 8 Manager30
 SG_ Manager30_ChargingMode_Status : 0|1@1+ (1,0) [0|1] "mode" Vector__XXX
CM_ BO_ 66127873 "CONFIRMED_CORRECT_DO_NOT_EDIT: Manager30 status frame. Raw CAN ID 0x03F10801, PGN 0x03F108, SA 0x01. D1 bit0 reports charging mode.";
CM_ SG_ 66127873 Manager30_ChargingMode_Status "CONFIRMED_CORRECT_DO_NOT_EDIT: D1 bit0 charging mode. 0=Touring, 1=Storage. Observed E4 during Touring and E5 during Storage after RedVision 0x43 command.";
VAL_ 66127873 Manager30_ChargingMode_Status 0 "Touring" 1 "Storage" ;
BA_ "Decode_Status" BO_ 66127873 "CONFIRMED_CORRECT_DO_NOT_EDIT";
BA_ "Decode_Status" SG_ 66127873 Manager30_ChargingMode_Status "CONFIRMED_CORRECT_DO_NOT_EDIT";

BO_ 66191361 PGN_03F200_Manager30_ChargingStage: 8 Manager30
 SG_ Manager30_ChargingStage : 0|8@1+ (1,0) [0|255] "stage" Vector__XXX
CM_ BO_ 66191361 "CONFIRMED_CORRECT_DO_NOT_EDIT: Manager30 fast charging stage/status frame. Raw CAN ID 0x03F20001, PGN 0x03F200, SA 0x01. D1 reports charging stage/state. D1 bit0 mirrors Touring/Storage: values ending in 1 are Storage mode.";
CM_ SG_ 66191361 Manager30_ChargingStage "CONFIRMED_CORRECT_DO_NOT_EDIT: D1 charging stage/status. 0x00/0x01=Not Charging, 0x21=Soft-start, 0x30/0x31=Boost, 0x40/0x41=Absorption, 0x70/0x71=Float, 0x80/0x81=Maintenance. Low bit 1 means Storage mode.";
VAL_ 66191361 Manager30_ChargingStage 0 "NotCharging" 1 "NotCharging_Storage" 33 "SoftStart" 48 "Boost" 49 "Boost_Storage" 64 "Absorption" 65 "Absorption_Storage" 112 "Float" 113 "Float_Storage" 128 "Maintenance" 129 "Maintenance_Storage" ;
BA_ "Decode_Status" BO_ 66191361 "CONFIRMED_CORRECT_DO_NOT_EDIT";
BA_ "Decode_Status" SG_ 66191361 Manager30_ChargingStage "CONFIRMED_CORRECT_DO_NOT_EDIT";

CM_ "v49 update: TVMS1280_Tank5_Percent corrected to raw percent scaling (1,0). Previous raw x 1.25 scaling removed.";

CM_ "v50 update: merged missing messages/signals from TVMS_Redvision_clean_separated_inputs_outputs(2).dbc into Current_SOC_v49_TVMS1280_Tank5_raw_percent(1).dbc. Existing v49 confirmed messages/signals were left unchanged. Every added message and signal from the inputs_outputs DBC is marked UNCONFIRMED_PENDING_TEST.";

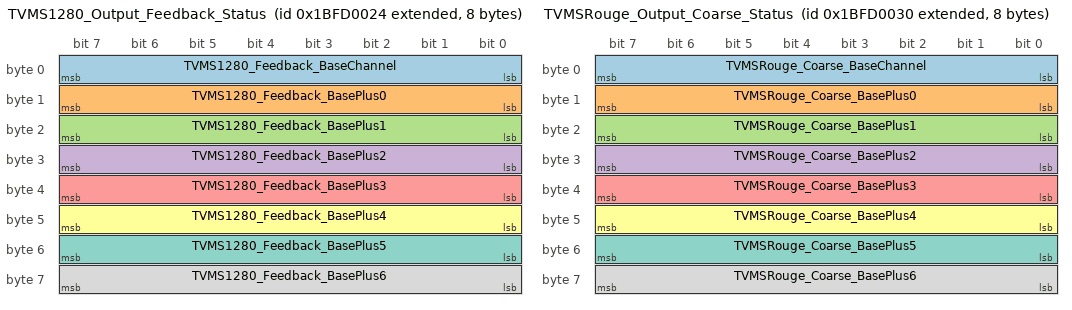
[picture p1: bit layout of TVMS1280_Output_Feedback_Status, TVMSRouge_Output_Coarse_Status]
BO_ 2617049124 TVMS1280_Output_Feedback_Status: 8 TVMS_1280
 SG_ TVMS1280_Feedback_BaseChannel : 0|8@1+ (1,0) [0|255] "channel" Vector__XXX
 SG_ TVMS1280_Feedback_BasePlus0 : 8|8@1+ (1,0) [0|255] "state" Vector__XXX
 SG_ TVMS1280_Feedback_BasePlus1 : 16|8@1+ (1,0) [0|255] "state" Vector__XXX
 SG_ TVMS1280_Feedback_BasePlus2 : 24|8@1+ (1,0) [0|255] "state" Vector__XXX
 SG_ TVMS1280_Feedback_BasePlus3 : 32|8@1+ (1,0) [0|255] "state" Vector__XXX
 SG_ TVMS1280_Feedback_BasePlus4 : 40|8@1+ (1,0) [0|255] "state" Vector__XXX
 SG_ TVMS1280_Feedback_BasePlus5 : 48|8@1+ (1,0) [0|255] "state" Vector__XXX
 SG_ TVMS1280_Feedback_BasePlus6 : 56|8@1+ (1,0) [0|255] "state" Vector__XXX
CM_ BO_ 2617049124 "PARTLY_CONFIRMED: TVMS1280 channel feedback. Raw CAN ID 0x1BFD0024, PGN 0x1BFD00, SA 0x24. D1 is base channel; D2-D8 are states for base+0..base+6. Output channels 0x04-0x0D are confirmed; digital input channels 0x01-0x03 are candidate/test entities.";
CM_ SG_ 2617049124 TVMS1280_Feedback_BaseChannel "D1 base channel. Example base 0x08 with D3=0x01 means channel 0x09 ON; D4 maps channel 0x0A. Candidate digital inputs should appear as channels 0x01, 0x02, and 0x03 if they share this feedback frame.";
CM_ SG_ 2617049124 TVMS1280_Feedback_BasePlus0 "State for channel base+0. 0x00=OFF, 0x01=ON, 0xF8/0xFF=unavailable/ignore.";
CM_ SG_ 2617049124 TVMS1280_Feedback_BasePlus1 "State for channel base+1. 0x00=OFF, 0x01=ON, 0xF8/0xFF=unavailable/ignore.";
CM_ SG_ 2617049124 TVMS1280_Feedback_BasePlus2 "State for channel base+2. 0x00=OFF, 0x01=ON, 0xF8/0xFF=unavailable/ignore.";
CM_ SG_ 2617049124 TVMS1280_Feedback_BasePlus3 "State for channel base+3. 0x00=OFF, 0x01=ON, 0xF8/0xFF=unavailable/ignore.";
CM_ SG_ 2617049124 TVMS1280_Feedback_BasePlus4 "State for channel base+4. 0x00=OFF, 0x01=ON, 0xF8/0xFF=unavailable/ignore.";
CM_ SG_ 2617049124 TVMS1280_Feedback_BasePlus5 "State for channel base+5. 0x00=OFF, 0x01=ON, 0xF8/0xFF=unavailable/ignore.";
CM_ SG_ 2617049124 TVMS1280_Feedback_BasePlus6 "State for channel base+6. 0x00=OFF, 0x01=ON, 0xF8/0xFF=unavailable/ignore.";
BA_ "Decode_Status" BO_ 2617049124 "PARTLY_CONFIRMED";
BA_ "Decode_Status" SG_ 2617049124 TVMS1280_Feedback_BaseChannel "PARTLY_CONFIRMED";
BA_ "Decode_Status" SG_ 2617049124 TVMS1280_Feedback_BasePlus0 "CONFIRMED_CORRECT_DO_NOT_EDIT";
BA_ "Decode_Status" SG_ 2617049124 TVMS1280_Feedback_BasePlus1 "CONFIRMED_CORRECT_DO_NOT_EDIT";
BA_ "Decode_Status" SG_ 2617049124 TVMS1280_Feedback_BasePlus2 "CONFIRMED_CORRECT_DO_NOT_EDIT";
BA_ "Decode_Status" SG_ 2617049124 TVMS1280_Feedback_BasePlus3 "CONFIRMED_CORRECT_DO_NOT_EDIT";
BA_ "Decode_Status" SG_ 2617049124 TVMS1280_Feedback_BasePlus4 "CONFIRMED_CORRECT_DO_NOT_EDIT";
BA_ "Decode_Status" SG_ 2617049124 TVMS1280_Feedback_BasePlus5 "CONFIRMED_CORRECT_DO_NOT_EDIT";
BA_ "Decode_Status" SG_ 2617049124 TVMS1280_Feedback_BasePlus6 "CONFIRMED_CORRECT_DO_NOT_EDIT";

BO_ 2399151136 TVMS1280_Command_From_Redvision1: 8 Redvision_1
 SG_ TVMS1280_Command_D1_Raw : 0|8@1+ (1,0) [0|255] "raw" Vector__XXX
 SG_ TVMS1280_Command_D2_Raw : 8|8@1+ (1,0) [0|255] "raw" Vector__XXX
 SG_ TVMS1280_Command_Channel M : 16|8@1+ (1,0) [0|255] "channel" Vector__XXX
 SG_ TVMS1280_Inverter_Command m14 : 24|1@1+ (1,0) [0|1] "bool" Vector__XXX
 SG_ TVMS1280_Master_Command m15 : 24|1@1+ (1,0) [0|1] "bool" Vector__XXX
 SG_ TVMS1280_Command_State_Raw : 24|8@1+ (1,0) [0|255] "raw" Vector__XXX
CM_ BO_ 2399151136 "UNCONFIRMED_PENDING_TEST: imported from inputs_outputs DBC. Original note: Raw CAN ID 0x0F002420, PGN 0x0F0024, source 0x20 Redvision_1. Logical commands from Redvision to TVMS_1280.";
CM_ SG_ 2399151136 TVMS1280_Inverter_Command "UNCONFIRMED_PENDING_TEST: imported from inputs_outputs DBC. Original note: Confirmed inverter enable command. Frame pattern D3=0x0E, D4=0x01 ON, D4=0x00 OFF.";
CM_ SG_ 2399151136 TVMS1280_Master_Command "UNCONFIRMED_PENDING_TEST: TVMS1280 config/label page identifies item/channel 0x0F as Master switch. ESPHome maps the master switch to the same on/off command shape as other TVMS1280 logical channels.";
VAL_ 2399151136 TVMS1280_Inverter_Command 0 "Off" 1 "On" ;
VAL_ 2399151136 TVMS1280_Master_Command 0 "Off" 1 "On" ;
CM_ SG_ 2399151136 TVMS1280_Command_D1_Raw "UNCONFIRMED_PENDING_TEST: imported from inputs_outputs DBC. Signal was not present in v49 and requires validation.";
CM_ SG_ 2399151136 TVMS1280_Command_D2_Raw "UNCONFIRMED_PENDING_TEST: imported from inputs_outputs DBC. Signal was not present in v49 and requires validation.";
CM_ SG_ 2399151136 TVMS1280_Command_Channel "UNCONFIRMED_PENDING_TEST: imported from inputs_outputs DBC. Signal was not present in v49 and requires validation.";
CM_ SG_ 2399151136 TVMS1280_Command_State_Raw "UNCONFIRMED_PENDING_TEST: imported from inputs_outputs DBC. Signal was not present in v49 and requires validation.";
BA_ "Decode_Status" BO_ 2399151136 "UNCONFIRMED_PENDING_TEST";
BA_ "Decode_Status" SG_ 2399151136 TVMS1280_Command_D1_Raw "UNCONFIRMED_PENDING_TEST";
BA_ "Decode_Status" SG_ 2399151136 TVMS1280_Command_D2_Raw "UNCONFIRMED_PENDING_TEST";
BA_ "Decode_Status" SG_ 2399151136 TVMS1280_Command_Channel "UNCONFIRMED_PENDING_TEST";
BA_ "Decode_Status" SG_ 2399151136 TVMS1280_Inverter_Command "UNCONFIRMED_PENDING_TEST";
BA_ "Decode_Status" SG_ 2399151136 TVMS1280_Master_Command "UNCONFIRMED_PENDING_TEST";
BA_ "Decode_Status" SG_ 2399151136 TVMS1280_Command_State_Raw "UNCONFIRMED_PENDING_TEST";

BO_ 2617049136 TVMSRouge_Output_Coarse_Status: 8 TVMS_Rouge
 SG_ TVMSRouge_Coarse_BaseChannel : 0|8@1+ (1,0) [0|255] "channel" Vector__XXX
 SG_ TVMSRouge_Coarse_BasePlus0 : 8|8@1+ (1,0) [0|255] "state" Vector__XXX
 SG_ TVMSRouge_Coarse_BasePlus1 : 16|8@1+ (1,0) [0|255] "state" Vector__XXX
 SG_ TVMSRouge_Coarse_BasePlus2 : 24|8@1+ (1,0) [0|255] "state" Vector__XXX
 SG_ TVMSRouge_Coarse_BasePlus3 : 32|8@1+ (1,0) [0|255] "state" Vector__XXX
 SG_ TVMSRouge_Coarse_BasePlus4 : 40|8@1+ (1,0) [0|255] "state" Vector__XXX
 SG_ TVMSRouge_Coarse_BasePlus5 : 48|8@1+ (1,0) [0|255] "state" Vector__XXX
 SG_ TVMSRouge_Coarse_BasePlus6 : 56|8@1+ (1,0) [0|255] "state" Vector__XXX
CM_ BO_ 2617049136 "CONFIRMED_CORRECT_DO_NOT_EDIT: TVMS Rouge physical input/button state. Raw CAN ID 0x1BFD0030, PGN 0x1FD00, SA 0x30. D1 is base input; D2-D8 are states for base+0..base+6. D1=0x01 covers inputs 1-7; D1=0x08 D2 covers input 8. 0x00=inactive, 0x01=active.";
CM_ SG_ 2617049136 TVMSRouge_Coarse_BaseChannel "D1 base input/channel. D1=0x01 maps D2-D8 to Rouge inputs/buttons 1-7. D1=0x08 maps D2 to Rouge input/button 8; later bytes in that frame are not physical button states.";
CM_ SG_ 2617049136 TVMSRouge_Coarse_BasePlus0 "Input/button state for base+0. 0x00=inactive, 0x01=active.";
CM_ SG_ 2617049136 TVMSRouge_Coarse_BasePlus1 "Input/button state for base+1. 0x00=inactive, 0x01=active.";
CM_ SG_ 2617049136 TVMSRouge_Coarse_BasePlus2 "Input/button state for base+2. 0x00=inactive, 0x01=active.";
CM_ SG_ 2617049136 TVMSRouge_Coarse_BasePlus3 "Input/button state for base+3. 0x00=inactive, 0x01=active.";
CM_ SG_ 2617049136 TVMSRouge_Coarse_BasePlus4 "Input/button state for base+4. 0x00=inactive, 0x01=active.";
CM_ SG_ 2617049136 TVMSRouge_Coarse_BasePlus5 "Input/button state for base+5. 0x00=inactive, 0x01=active.";
CM_ SG_ 2617049136 TVMSRouge_Coarse_BasePlus6 "Input/button state for base+6. 0x00=inactive, 0x01=active.";
BA_ "Decode_Status" BO_ 2617049136 "CONFIRMED_CORRECT_DO_NOT_EDIT";
BA_ "Decode_Status" SG_ 2617049136 TVMSRouge_Coarse_BaseChannel "CONFIRMED_CORRECT_DO_NOT_EDIT";
BA_ "Decode_Status" SG_ 2617049136 TVMSRouge_Coarse_BasePlus0 "CONFIRMED_CORRECT_DO_NOT_EDIT";
BA_ "Decode_Status" SG_ 2617049136 TVMSRouge_Coarse_BasePlus1 "CONFIRMED_CORRECT_DO_NOT_EDIT";
BA_ "Decode_Status" SG_ 2617049136 TVMSRouge_Coarse_BasePlus2 "CONFIRMED_CORRECT_DO_NOT_EDIT";
BA_ "Decode_Status" SG_ 2617049136 TVMSRouge_Coarse_BasePlus3 "CONFIRMED_CORRECT_DO_NOT_EDIT";
BA_ "Decode_Status" SG_ 2617049136 TVMSRouge_Coarse_BasePlus4 "CONFIRMED_CORRECT_DO_NOT_EDIT";
BA_ "Decode_Status" SG_ 2617049136 TVMSRouge_Coarse_BasePlus5 "CONFIRMED_CORRECT_DO_NOT_EDIT";
BA_ "Decode_Status" SG_ 2617049136 TVMSRouge_Coarse_BasePlus6 "CONFIRMED_CORRECT_DO_NOT_EDIT";

BO_ 2617246256 TVMSRouge_WaterLevelStatus: 8 TVMS_Rouge
 SG_ WaterLevel_MUX M : 0|8@1+ (1,0) [0|255] "" Vector__XXX
 SG_ Rouge_Tank1_Percent m9 : 8|8@1+ (1,0) [0|100] "%" Vector__XXX
 SG_ Rouge_Tank2_Percent m9 : 16|8@1+ (1,0) [0|100] "%" Vector__XXX
CM_ BO_ 2617246256 "UNCONFIRMED_PENDING_TEST: imported from inputs_outputs DBC. Original note: Raw CAN ID 0x1C000230, PGN 0x1C0002, source 0x30 TVMS_Rouge. Dual water tank level status from supplied DBC.";
CM_ SG_ 2617246256 WaterLevel_MUX "UNCONFIRMED_PENDING_TEST: imported from inputs_outputs DBC. Original note: Multiplexor: 0x09 = TankLevels, 0x16 = Reserved.";
CM_ SG_ 2617246256 Rouge_Tank1_Percent "UNCONFIRMED_PENDING_TEST: imported from inputs_outputs DBC. Original note: Confirmed fresh water tank 1 fill level.";
CM_ SG_ 2617246256 Rouge_Tank2_Percent "UNCONFIRMED_PENDING_TEST: imported from inputs_outputs DBC. Original note: Confirmed fresh water tank 2 fill level.";
VAL_ 2617246256 WaterLevel_MUX 9 "TankLevels" 22 "Reserved" ;
BA_ "Decode_Status" BO_ 2617246256 "UNCONFIRMED_PENDING_TEST";
BA_ "Decode_Status" SG_ 2617246256 WaterLevel_MUX "UNCONFIRMED_PENDING_TEST";
BA_ "Decode_Status" SG_ 2617246256 Rouge_Tank1_Percent "UNCONFIRMED_PENDING_TEST";
BA_ "Decode_Status" SG_ 2617246256 Rouge_Tank2_Percent "UNCONFIRMED_PENDING_TEST";

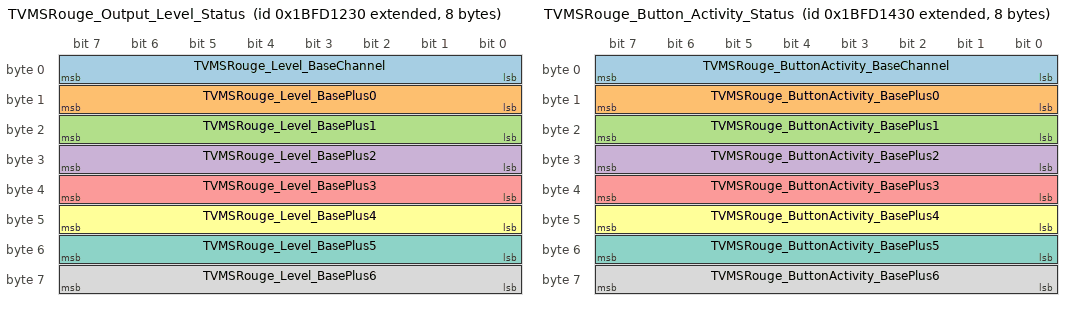
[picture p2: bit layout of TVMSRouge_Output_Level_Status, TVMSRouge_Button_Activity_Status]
BO_ 2617053744 TVMSRouge_Output_Level_Status: 8 TVMS_Rouge
 SG_ TVMSRouge_Level_BaseChannel : 0|8@1+ (1,0) [0|255] "channel" Vector__XXX
 SG_ TVMSRouge_Level_BasePlus0 : 8|8@1+ (1,0) [0|100] "%" Vector__XXX
 SG_ TVMSRouge_Level_BasePlus1 : 16|8@1+ (1,0) [0|100] "%" Vector__XXX
 SG_ TVMSRouge_Level_BasePlus2 : 24|8@1+ (1,0) [0|100] "%" Vector__XXX
 SG_ TVMSRouge_Level_BasePlus3 : 32|8@1+ (1,0) [0|100] "%" Vector__XXX
 SG_ TVMSRouge_Level_BasePlus4 : 40|8@1+ (1,0) [0|100] "%" Vector__XXX
 SG_ TVMSRouge_Level_BasePlus5 : 48|8@1+ (1,0) [0|100] "%" Vector__XXX
 SG_ TVMSRouge_Level_BasePlus6 : 56|8@1+ (1,0) [0|100] "%" Vector__XXX
CM_ BO_ 2617053744 "CONFIRMED_CORRECT_DO_NOT_EDIT: TVMS Rouge actual output brightness/level feedback. Raw CAN ID 0x1BFD1230, PGN 0x1BFD12, SA 0x30. D1 is base channel; D2-D8 are brightness levels for base+0..base+6 in raw percent.";
CM_ SG_ 2617053744 TVMSRouge_Level_BaseChannel "D1 base channel. Base 0x0C covers Rouge Outputs 1-7/channels 0x0C-0x12. Base 0x13 covers Outputs 8-10/channels 0x13-0x15.";
CM_ SG_ 2617053744 TVMSRouge_Level_BasePlus0 "Brightness percent for channel base+0.";
CM_ SG_ 2617053744 TVMSRouge_Level_BasePlus1 "Brightness percent for channel base+1.";
CM_ SG_ 2617053744 TVMSRouge_Level_BasePlus2 "Brightness percent for channel base+2.";
CM_ SG_ 2617053744 TVMSRouge_Level_BasePlus3 "Brightness percent for channel base+3.";
CM_ SG_ 2617053744 TVMSRouge_Level_BasePlus4 "Brightness percent for channel base+4.";
CM_ SG_ 2617053744 TVMSRouge_Level_BasePlus5 "Brightness percent for channel base+5.";
CM_ SG_ 2617053744 TVMSRouge_Level_BasePlus6 "Brightness percent for channel base+6.";
BA_ "Decode_Status" BO_ 2617053744 "CONFIRMED_CORRECT_DO_NOT_EDIT";
BA_ "Decode_Status" SG_ 2617053744 TVMSRouge_Level_BaseChannel "CONFIRMED_CORRECT_DO_NOT_EDIT";
BA_ "Decode_Status" SG_ 2617053744 TVMSRouge_Level_BasePlus0 "CONFIRMED_CORRECT_DO_NOT_EDIT";
BA_ "Decode_Status" SG_ 2617053744 TVMSRouge_Level_BasePlus1 "CONFIRMED_CORRECT_DO_NOT_EDIT";
BA_ "Decode_Status" SG_ 2617053744 TVMSRouge_Level_BasePlus2 "CONFIRMED_CORRECT_DO_NOT_EDIT";
BA_ "Decode_Status" SG_ 2617053744 TVMSRouge_Level_BasePlus3 "CONFIRMED_CORRECT_DO_NOT_EDIT";
BA_ "Decode_Status" SG_ 2617053744 TVMSRouge_Level_BasePlus4 "CONFIRMED_CORRECT_DO_NOT_EDIT";
BA_ "Decode_Status" SG_ 2617053744 TVMSRouge_Level_BasePlus5 "CONFIRMED_CORRECT_DO_NOT_EDIT";
BA_ "Decode_Status" SG_ 2617053744 TVMSRouge_Level_BasePlus6 "CONFIRMED_CORRECT_DO_NOT_EDIT";

BO_ 2617054256 TVMSRouge_Button_Activity_Status: 8 TVMS_Rouge
 SG_ TVMSRouge_ButtonActivity_BaseChannel : 0|8@1+ (1,0) [0|255] "channel" Vector__XXX
 SG_ TVMSRouge_ButtonActivity_BasePlus0 : 8|8@1+ (1,0) [0|255] "state" Vector__XXX
 SG_ TVMSRouge_ButtonActivity_BasePlus1 : 16|8@1+ (1,0) [0|255] "state" Vector__XXX
 SG_ TVMSRouge_ButtonActivity_BasePlus2 : 24|8@1+ (1,0) [0|255] "state" Vector__XXX
 SG_ TVMSRouge_ButtonActivity_BasePlus3 : 32|8@1+ (1,0) [0|255] "state" Vector__XXX
 SG_ TVMSRouge_ButtonActivity_BasePlus4 : 40|8@1+ (1,0) [0|255] "state" Vector__XXX
 SG_ TVMSRouge_ButtonActivity_BasePlus5 : 48|8@1+ (1,0) [0|255] "state" Vector__XXX
 SG_ TVMSRouge_ButtonActivity_BasePlus6 : 56|8@1+ (1,0) [0|255] "state" Vector__XXX
CM_ BO_ 2617054256 "CONFIRMED_CORRECT_DO_NOT_EDIT: TVMS Rouge output button/dimming-active/status frame, not the real physical input/button state. Raw CAN ID 0x1BFD1430, PGN 0x1BFD14, SA 0x30. In button 4-8 testing this frame stayed idle while 0x1BFD0030 carried actual input states.";
CM_ SG_ 2617054256 TVMSRouge_ButtonActivity_BaseChannel "D1 base channel for output/dimming activity. Do not use this frame as the Rouge physical input/button state; use 0x1BFD0030 instead.";
CM_ SG_ 2617054256 TVMSRouge_ButtonActivity_BasePlus0 "Button/dimming activity for channel base+0. 0x02=active/held/dimming, 0x00=inactive, other values ignored.";
CM_ SG_ 2617054256 TVMSRouge_ButtonActivity_BasePlus1 "Button/dimming activity for channel base+1. 0x02=active/held/dimming, 0x00=inactive, other values ignored.";
CM_ SG_ 2617054256 TVMSRouge_ButtonActivity_BasePlus2 "Button/dimming activity for channel base+2. 0x02=active/held/dimming, 0x00=inactive, other values ignored.";
CM_ SG_ 2617054256 TVMSRouge_ButtonActivity_BasePlus3 "Button/dimming activity for channel base+3. 0x02=active/held/dimming, 0x00=inactive, other values ignored.";
CM_ SG_ 2617054256 TVMSRouge_ButtonActivity_BasePlus4 "Button/dimming activity for channel base+4. 0x02=active/held/dimming, 0x00=inactive, other values ignored.";
CM_ SG_ 2617054256 TVMSRouge_ButtonActivity_BasePlus5 "Button/dimming activity for channel base+5. 0x02=active/held/dimming, 0x00=inactive, other values ignored.";
CM_ SG_ 2617054256 TVMSRouge_ButtonActivity_BasePlus6 "Button/dimming activity for channel base+6. 0x02=active/held/dimming, 0x00=inactive, other values ignored.";
BA_ "Decode_Status" BO_ 2617054256 "CONFIRMED_CORRECT_DO_NOT_EDIT";
BA_ "Decode_Status" SG_ 2617054256 TVMSRouge_ButtonActivity_BaseChannel "CONFIRMED_CORRECT_DO_NOT_EDIT";
BA_ "Decode_Status" SG_ 2617054256 TVMSRouge_ButtonActivity_BasePlus0 "CONFIRMED_CORRECT_DO_NOT_EDIT";
BA_ "Decode_Status" SG_ 2617054256 TVMSRouge_ButtonActivity_BasePlus1 "CONFIRMED_CORRECT_DO_NOT_EDIT";
BA_ "Decode_Status" SG_ 2617054256 TVMSRouge_ButtonActivity_BasePlus2 "CONFIRMED_CORRECT_DO_NOT_EDIT";
BA_ "Decode_Status" SG_ 2617054256 TVMSRouge_ButtonActivity_BasePlus3 "CONFIRMED_CORRECT_DO_NOT_EDIT";
BA_ "Decode_Status" SG_ 2617054256 TVMSRouge_ButtonActivity_BasePlus4 "CONFIRMED_CORRECT_DO_NOT_EDIT";
BA_ "Decode_Status" SG_ 2617054256 TVMSRouge_ButtonActivity_BasePlus5 "CONFIRMED_CORRECT_DO_NOT_EDIT";
BA_ "Decode_Status" SG_ 2617054256 TVMSRouge_ButtonActivity_BasePlus6 "CONFIRMED_CORRECT_DO_NOT_EDIT";

BO_ 2399154208 TVMSRouge_Command_From_Redvision1: 8 Redvision_1
 SG_ TVMSRouge_Command_D1_Raw : 0|8@1+ (1,0) [0|255] "raw" Vector__XXX
 SG_ TVMSRouge_Command_D2_Raw : 8|8@1+ (1,0) [0|255] "raw" Vector__XXX
 SG_ TVMSRouge_Command_Channel M : 24|8@1+ (1,0) [0|255] "channel" Vector__XXX
 SG_ TVMSRouge_Command_State : 32|8@1+ (1,0) [0|255] "state" Vector__XXX
 SG_ TVMSRouge_Master_OnOffCmd m11 : 32|1@1+ (1,0) [0|1] "bool" Vector__XXX
 SG_ Rouge_Output_01_OnOffCmd m12 : 32|1@1+ (1,0) [0|1] "bool" Vector__XXX
 SG_ Rouge_Output_02_OnOffCmd m13 : 32|1@1+ (1,0) [0|1] "bool" Vector__XXX
 SG_ Rouge_Output_03_OnOffCmd m14 : 32|1@1+ (1,0) [0|1] "bool" Vector__XXX
 SG_ Rouge_Output_04_OnOffCmd m15 : 32|1@1+ (1,0) [0|1] "bool" Vector__XXX
 SG_ Rouge_Output_05_OnOffCmd m16 : 32|1@1+ (1,0) [0|1] "bool" Vector__XXX
 SG_ Rouge_Output_06_OnOffCmd m17 : 32|1@1+ (1,0) [0|1] "bool" Vector__XXX
 SG_ Rouge_Output_07_OnOffCmd m18 : 32|1@1+ (1,0) [0|1] "bool" Vector__XXX
 SG_ Rouge_Output_08_OnOffCmd m19 : 32|1@1+ (1,0) [0|1] "bool" Vector__XXX
 SG_ Rouge_Output_09_OnOffCmd m20 : 32|1@1+ (1,0) [0|1] "bool" Vector__XXX
 SG_ Rouge_Output_10_OnOffCmd m21 : 32|1@1+ (1,0) [0|1] "bool" Vector__XXX
CM_ BO_ 2399154208 "UNCONFIRMED_PENDING_TEST: imported from inputs_outputs DBC. Original note: Raw CAN ID 0x0F003020, PGN 0x0F0030, source 0x20 Redvision_1. Logical Redvision commands to Rouge outputs; not physical button mapping.";
VAL_ 2399154208 TVMSRouge_Command_Channel 11 "Master" 12 "Output_1" 13 "Output_2" 14 "Output_3" 15 "Output_4" 16 "Output_5" 17 "Output_6" 18 "Output_7" 19 "Output_8" 20 "Output_9" 21 "Output_10" ;
CM_ SG_ 2399154208 TVMSRouge_Command_D1_Raw "UNCONFIRMED_PENDING_TEST: imported from inputs_outputs DBC. Signal was not present in v49 and requires validation.";
CM_ SG_ 2399154208 TVMSRouge_Command_D2_Raw "UNCONFIRMED_PENDING_TEST: imported from inputs_outputs DBC. Signal was not present in v49 and requires validation.";
CM_ SG_ 2399154208 TVMSRouge_Command_Channel "UNCONFIRMED_PENDING_TEST: imported from inputs_outputs DBC. Signal was not present in v49 and requires validation.";
CM_ SG_ 2399154208 TVMSRouge_Command_State "UNCONFIRMED_PENDING_TEST: imported from inputs_outputs DBC. Signal was not present in v49 and requires validation.";
CM_ SG_ 2399154208 TVMSRouge_Master_OnOffCmd "UNCONFIRMED_PENDING_TEST: TVMS Rouge config/label page identifies item/channel 0x0B as Master. ESPHome maps the master switch to the same on/off command shape as other Rouge logical channels.";
CM_ SG_ 2399154208 Rouge_Output_01_OnOffCmd "UNCONFIRMED_PENDING_TEST: imported from inputs_outputs DBC. Signal was not present in v49 and requires validation.";
CM_ SG_ 2399154208 Rouge_Output_02_OnOffCmd "UNCONFIRMED_PENDING_TEST: imported from inputs_outputs DBC. Signal was not present in v49 and requires validation.";
CM_ SG_ 2399154208 Rouge_Output_03_OnOffCmd "UNCONFIRMED_PENDING_TEST: imported from inputs_outputs DBC. Signal was not present in v49 and requires validation.";
CM_ SG_ 2399154208 Rouge_Output_04_OnOffCmd "UNCONFIRMED_PENDING_TEST: imported from inputs_outputs DBC. Signal was not present in v49 and requires validation.";
CM_ SG_ 2399154208 Rouge_Output_05_OnOffCmd "UNCONFIRMED_PENDING_TEST: imported from inputs_outputs DBC. Signal was not present in v49 and requires validation.";
CM_ SG_ 2399154208 Rouge_Output_06_OnOffCmd "UNCONFIRMED_PENDING_TEST: imported from inputs_outputs DBC. Signal was not present in v49 and requires validation.";
CM_ SG_ 2399154208 Rouge_Output_07_OnOffCmd "UNCONFIRMED_PENDING_TEST: imported from inputs_outputs DBC. Signal was not present in v49 and requires validation.";
CM_ SG_ 2399154208 Rouge_Output_08_OnOffCmd "UNCONFIRMED_PENDING_TEST: imported from inputs_outputs DBC. Signal was not present in v49 and requires validation.";
CM_ SG_ 2399154208 Rouge_Output_09_OnOffCmd "UNCONFIRMED_PENDING_TEST: imported from inputs_outputs DBC. Signal was not present in v49 and requires validation.";
CM_ SG_ 2399154208 Rouge_Output_10_OnOffCmd "UNCONFIRMED_PENDING_TEST: imported from inputs_outputs DBC. Signal was not present in v49 and requires validation.";
BA_ "Decode_Status" BO_ 2399154208 "UNCONFIRMED_PENDING_TEST";
BA_ "Decode_Status" SG_ 2399154208 TVMSRouge_Command_D1_Raw "UNCONFIRMED_PENDING_TEST";
BA_ "Decode_Status" SG_ 2399154208 TVMSRouge_Command_D2_Raw "UNCONFIRMED_PENDING_TEST";
BA_ "Decode_Status" SG_ 2399154208 TVMSRouge_Command_Channel "UNCONFIRMED_PENDING_TEST";
BA_ "Decode_Status" SG_ 2399154208 TVMSRouge_Command_State "UNCONFIRMED_PENDING_TEST";
BA_ "Decode_Status" SG_ 2399154208 TVMSRouge_Master_OnOffCmd "UNCONFIRMED_PENDING_TEST";
BA_ "Decode_Status" SG_ 2399154208 Rouge_Output_01_OnOffCmd "UNCONFIRMED_PENDING_TEST";
BA_ "Decode_Status" SG_ 2399154208 Rouge_Output_02_OnOffCmd "UNCONFIRMED_PENDING_TEST";
BA_ "Decode_Status" SG_ 2399154208 Rouge_Output_03_OnOffCmd "UNCONFIRMED_PENDING_TEST";
BA_ "Decode_Status" SG_ 2399154208 Rouge_Output_04_OnOffCmd "UNCONFIRMED_PENDING_TEST";
BA_ "Decode_Status" SG_ 2399154208 Rouge_Output_05_OnOffCmd "UNCONFIRMED_PENDING_TEST";
BA_ "Decode_Status" SG_ 2399154208 Rouge_Output_06_OnOffCmd "UNCONFIRMED_PENDING_TEST";
BA_ "Decode_Status" SG_ 2399154208 Rouge_Output_07_OnOffCmd "UNCONFIRMED_PENDING_TEST";
BA_ "Decode_Status" SG_ 2399154208 Rouge_Output_08_OnOffCmd "UNCONFIRMED_PENDING_TEST";
BA_ "Decode_Status" SG_ 2399154208 Rouge_Output_09_OnOffCmd "UNCONFIRMED_PENDING_TEST";
BA_ "Decode_Status" SG_ 2399154208 Rouge_Output_10_OnOffCmd "UNCONFIRMED_PENDING_TEST";

BO_ 2399219744 TVMSRouge_Dim_Command: 8 Redvision_1
 SG_ TVMSRouge_Dim_Channel M : 0|8@1+ (1,0) [0|255] "channel" Vector__XXX
 SG_ TVMSRouge_Dim_Enable : 8|8@1+ (1,0) [0|255] "raw" Vector__XXX
 SG_ Rouge_Output_01_TargetLevel m12 : 16|8@1+ (1,0) [0|100] "%" Vector__XXX
 SG_ Rouge_Output_02_TargetLevel m13 : 16|8@1+ (1,0) [0|100] "%" Vector__XXX
 SG_ Rouge_Output_03_TargetLevel m14 : 16|8@1+ (1,0) [0|100] "%" Vector__XXX
 SG_ Rouge_Output_04_TargetLevel m15 : 16|8@1+ (1,0) [0|100] "%" Vector__XXX
 SG_ Rouge_Output_05_TargetLevel m16 : 16|8@1+ (1,0) [0|100] "%" Vector__XXX
 SG_ Rouge_Output_06_TargetLevel m17 : 16|8@1+ (1,0) [0|100] "%" Vector__XXX
 SG_ Rouge_Output_07_TargetLevel m18 : 16|8@1+ (1,0) [0|100] "%" Vector__XXX
 SG_ Rouge_Output_08_TargetLevel m19 : 16|8@1+ (1,0) [0|100] "%" Vector__XXX
 SG_ Rouge_Output_09_TargetLevel m20 : 16|8@1+ (1,0) [0|100] "%" Vector__XXX
 SG_ Rouge_Output_10_TargetLevel m21 : 16|8@1+ (1,0) [0|100] "%" Vector__XXX
CM_ BO_ 2399219744 "UNCONFIRMED_PENDING_TEST: imported from inputs_outputs DBC. Original note: Raw CAN ID 0x0F013020, PGN 0x0F0130. Logical dim command. Channel IDs 0x0C-0x15 are Rouge outputs 1-10.";
VAL_ 2399219744 TVMSRouge_Dim_Channel 12 "Output_1" 13 "Output_2" 14 "Output_3" 15 "Output_4" 16 "Output_5" 17 "Output_6" 18 "Output_7" 19 "Output_8" 20 "Output_9" 21 "Output_10" ;
CM_ SG_ 2399219744 TVMSRouge_Dim_Channel "UNCONFIRMED_PENDING_TEST: imported from inputs_outputs DBC. Signal was not present in v49 and requires validation.";
CM_ SG_ 2399219744 TVMSRouge_Dim_Enable "UNCONFIRMED_PENDING_TEST: imported from inputs_outputs DBC. Signal was not present in v49 and requires validation.";
CM_ SG_ 2399219744 Rouge_Output_01_TargetLevel "UNCONFIRMED_PENDING_TEST: imported from inputs_outputs DBC. Signal was not present in v49 and requires validation.";
CM_ SG_ 2399219744 Rouge_Output_02_TargetLevel "UNCONFIRMED_PENDING_TEST: imported from inputs_outputs DBC. Signal was not present in v49 and requires validation.";
CM_ SG_ 2399219744 Rouge_Output_03_TargetLevel "UNCONFIRMED_PENDING_TEST: imported from inputs_outputs DBC. Signal was not present in v49 and requires validation.";
CM_ SG_ 2399219744 Rouge_Output_04_TargetLevel "UNCONFIRMED_PENDING_TEST: imported from inputs_outputs DBC. Signal was not present in v49 and requires validation.";
CM_ SG_ 2399219744 Rouge_Output_05_TargetLevel "UNCONFIRMED_PENDING_TEST: imported from inputs_outputs DBC. Signal was not present in v49 and requires validation.";
CM_ SG_ 2399219744 Rouge_Output_06_TargetLevel "UNCONFIRMED_PENDING_TEST: imported from inputs_outputs DBC. Signal was not present in v49 and requires validation.";
CM_ SG_ 2399219744 Rouge_Output_07_TargetLevel "UNCONFIRMED_PENDING_TEST: imported from inputs_outputs DBC. Signal was not present in v49 and requires validation.";
CM_ SG_ 2399219744 Rouge_Output_08_TargetLevel "UNCONFIRMED_PENDING_TEST: imported from inputs_outputs DBC. Signal was not present in v49 and requires validation.";
CM_ SG_ 2399219744 Rouge_Output_09_TargetLevel "UNCONFIRMED_PENDING_TEST: imported from inputs_outputs DBC. Signal was not present in v49 and requires validation.";
CM_ SG_ 2399219744 Rouge_Output_10_TargetLevel "UNCONFIRMED_PENDING_TEST: imported from inputs_outputs DBC. Signal was not present in v49 and requires validation.";
BA_ "Decode_Status" BO_ 2399219744 "UNCONFIRMED_PENDING_TEST";
BA_ "Decode_Status" SG_ 2399219744 TVMSRouge_Dim_Channel "UNCONFIRMED_PENDING_TEST";
BA_ "Decode_Status" SG_ 2399219744 TVMSRouge_Dim_Enable "UNCONFIRMED_PENDING_TEST";
BA_ "Decode_Status" SG_ 2399219744 Rouge_Output_01_TargetLevel "UNCONFIRMED_PENDING_TEST";
BA_ "Decode_Status" SG_ 2399219744 Rouge_Output_02_TargetLevel "UNCONFIRMED_PENDING_TEST";
BA_ "Decode_Status" SG_ 2399219744 Rouge_Output_03_TargetLevel "UNCONFIRMED_PENDING_TEST";
BA_ "Decode_Status" SG_ 2399219744 Rouge_Output_04_TargetLevel "UNCONFIRMED_PENDING_TEST";
BA_ "Decode_Status" SG_ 2399219744 Rouge_Output_05_TargetLevel "UNCONFIRMED_PENDING_TEST";
BA_ "Decode_Status" SG_ 2399219744 Rouge_Output_06_TargetLevel "UNCONFIRMED_PENDING_TEST";
BA_ "Decode_Status" SG_ 2399219744 Rouge_Output_07_TargetLevel "UNCONFIRMED_PENDING_TEST";
BA_ "Decode_Status" SG_ 2399219744 Rouge_Output_08_TargetLevel "UNCONFIRMED_PENDING_TEST";
BA_ "Decode_Status" SG_ 2399219744 Rouge_Output_09_TargetLevel "UNCONFIRMED_PENDING_TEST";
BA_ "Decode_Status" SG_ 2399219744 Rouge_Output_10_TargetLevel "UNCONFIRMED_PENDING_TEST";

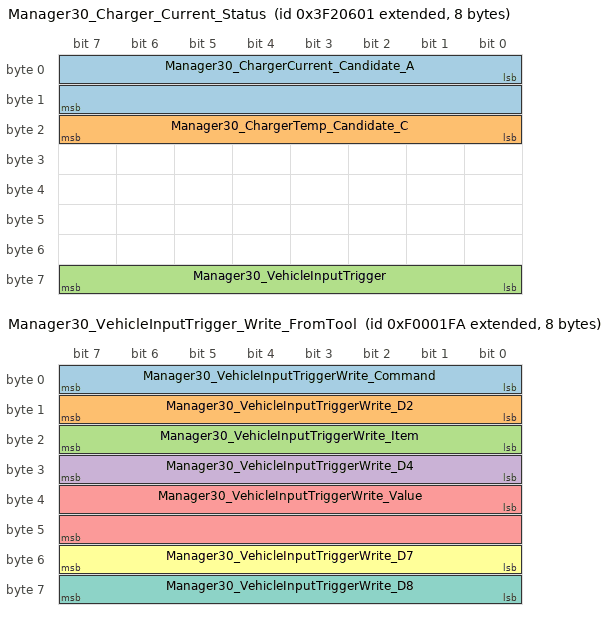
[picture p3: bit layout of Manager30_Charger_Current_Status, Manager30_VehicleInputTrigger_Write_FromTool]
BO_ 2213676545 Manager30_Charger_Current_Status: 8 Manager30
 SG_ Manager30_ChargerCurrent_Candidate_A : 0|16@1+ (0.01,0) [0|200] "A" Vector__XXX
 SG_ Manager30_ChargerTemp_Candidate_C : 16|8@1+ (1,-100) [-100|155] "degC" Vector__XXX
 SG_ Manager30_VehicleInputTrigger : 56|8@1+ (1,0) [0|5] "trigger" Vector__XXX
CM_ BO_ 2213676545 "PARTLY_CONFIRMED: Manager30 charger/status frame. Raw CAN ID 0x03F20601, private DGN 0x1F206, source 0x01 Manager30. D8 reports vehicle input trigger. Older charger current/temp candidates remain unconfirmed.";
CM_ SG_ 2213676545 Manager30_ChargerCurrent_Candidate_A "UNCONFIRMED_PENDING_TEST: imported from inputs_outputs DBC. Signal was not present in v49 and requires validation.";
CM_ SG_ 2213676545 Manager30_ChargerTemp_Candidate_C "UNCONFIRMED_PENDING_TEST: imported from inputs_outputs DBC. Signal was not present in v49 and requires validation.";
CM_ SG_ 2213676545 Manager30_VehicleInputTrigger "CONFIRMED_CORRECT_DO_NOT_EDIT: D8 reports vehicle input trigger. charger input trigger.csv sequence: 0=Auto, 1=12V, 2=24V, 3=Ignition, 5=On.";
VAL_ 2213676545 Manager30_VehicleInputTrigger 0 "Auto" 1 "12V" 2 "24V" 3 "Ignition" 5 "On" ;
BA_ "Decode_Status" BO_ 2213676545 "PARTLY_CONFIRMED";
BA_ "Decode_Status" SG_ 2213676545 Manager30_ChargerCurrent_Candidate_A "UNCONFIRMED_PENDING_TEST";
BA_ "Decode_Status" SG_ 2213676545 Manager30_ChargerTemp_Candidate_C "UNCONFIRMED_PENDING_TEST";
BA_ "Decode_Status" SG_ 2213676545 Manager30_VehicleInputTrigger "CONFIRMED_CORRECT_DO_NOT_EDIT";

BO_ 2399142394 Manager30_VehicleInputTrigger_Write_FromTool: 8 Config_Tool
 SG_ Manager30_VehicleInputTriggerWrite_Command : 0|8@1+ (1,0) [0|255] "raw" Vector__XXX
 SG_ Manager30_VehicleInputTriggerWrite_D2 : 8|8@1+ (1,0) [0|255] "raw" Vector__XXX
 SG_ Manager30_VehicleInputTriggerWrite_Item : 16|8@1+ (1,0) [0|255] "raw" Vector__XXX
 SG_ Manager30_VehicleInputTriggerWrite_D4 : 24|8@1+ (1,0) [0|255] "raw" Vector__XXX
 SG_ Manager30_VehicleInputTriggerWrite_Value : 32|16@1+ (1,0) [0|5] "trigger" Vector__XXX
 SG_ Manager30_VehicleInputTriggerWrite_D7 : 48|8@1+ (1,0) [0|255] "raw" Vector__XXX
 SG_ Manager30_VehicleInputTriggerWrite_D8 : 56|8@1+ (1,0) [0|255] "raw" Vector__XXX
CM_ BO_ 2399142394 "CONFIRMED_CORRECT_DO_NOT_EDIT: Manager30 vehicle input trigger config write from source 0xFA to Manager30 destination 0x01. Raw CAN ID 0x0F0001FA. Payload pattern 68 00 03 00 <trigger little-endian> 00 00 00.";
CM_ SG_ 2399142394 Manager30_VehicleInputTriggerWrite_Command "D1 observed 0x68 for vehicle input trigger write.";
CM_ SG_ 2399142394 Manager30_VehicleInputTriggerWrite_Item "D3 observed 0x03 for this config write.";
CM_ SG_ 2399142394 Manager30_VehicleInputTriggerWrite_Value "D5-D6 little-endian trigger value. Confirmed sequence: 0=Auto, 1=12V, 2=24V, 3=Ignition, 5=On.";
VAL_ 2399142394 Manager30_VehicleInputTriggerWrite_Value 0 "Auto" 1 "12V" 2 "24V" 3 "Ignition" 5 "On" ;
BA_ "Decode_Status" BO_ 2399142394 "CONFIRMED_CORRECT_DO_NOT_EDIT";
BA_ "Decode_Status" SG_ 2399142394 Manager30_VehicleInputTriggerWrite_Command "CONFIRMED_CORRECT_DO_NOT_EDIT";
BA_ "Decode_Status" SG_ 2399142394 Manager30_VehicleInputTriggerWrite_D2 "UNCONFIRMED_PENDING_TEST";
BA_ "Decode_Status" SG_ 2399142394 Manager30_VehicleInputTriggerWrite_Item "CONFIRMED_CORRECT_DO_NOT_EDIT";
BA_ "Decode_Status" SG_ 2399142394 Manager30_VehicleInputTriggerWrite_D4 "UNCONFIRMED_PENDING_TEST";
BA_ "Decode_Status" SG_ 2399142394 Manager30_VehicleInputTriggerWrite_Value "CONFIRMED_CORRECT_DO_NOT_EDIT";
BA_ "Decode_Status" SG_ 2399142394 Manager30_VehicleInputTriggerWrite_D7 "UNCONFIRMED_PENDING_TEST";
BA_ "Decode_Status" SG_ 2399142394 Manager30_VehicleInputTriggerWrite_D8 "UNCONFIRMED_PENDING_TEST";

BO_ 2482047496 BatterySensor_Load_Status: 8 Battery_Sensor
 SG_ BatterySensor_LoadCurrent_Candidate_A : 0|16@1+ (0.01,0) [0|200] "A" Vector__XXX
 SG_ Battery_Low_SOC_Alarm_Report_Percent : 8|8@1+ (1,0) [0|100] "%" Vector__XXX
 SG_ Battery_Low_Voltage_Alarm_Report_V : 16|16@1+ (0.001,0) [0|60] "V" Vector__XXX
CM_ BO_ 2482047496 "PARTLY_CONFIRMED: Battery Sensor status/config report. Raw CAN ID 0x13F10A08, private DGN 0x1F10A, source 0x08 Battery_Sensor. D2 reports low SOC alarm percent. D3-D4 little-endian reports low voltage alarm in millivolts. Older load-current candidate remains unconfirmed.";

BA_ "VFrameFormat" BO_ 2617049636 1;
BA_ "VFrameFormat" BO_ 2617049124 1;
BA_ "VFrameFormat" BO_ 2399151136 1;
BA_ "VFrameFormat" BO_ 2617049136 1;
BA_ "VFrameFormat" BO_ 2617049648 1;
BA_ "VFrameFormat" BO_ 2617246256 1;
BA_ "VFrameFormat" BO_ 2617053744 1;
BA_ "VFrameFormat" BO_ 2617054256 1;
BA_ "VFrameFormat" BO_ 2399154208 1;
BA_ "VFrameFormat" BO_ 2399219744 1;
BA_ "VFrameFormat" BO_ 2213677569 1;
BA_ "VFrameFormat" BO_ 2213676033 1;
BA_ "VFrameFormat" BO_ 2213676545 1;
BA_ "VFrameFormat" BO_ 2213677057 1;
BA_ "VFrameFormat" BO_ 2213741569 1;
BA_ "VFrameFormat" BO_ 2482045448 1;
BA_ "VFrameFormat" BO_ 2482044936 1;
BA_ "VFrameFormat" BO_ 2399144186 1;
BA_ "VFrameFormat" BO_ 2399142394 1;
BA_ "VFrameFormat" BO_ 2399207200 1;
BA_ "VFrameFormat" BO_ 2482047496 1;
BA_ "VFrameFormat" BO_ 2482047012 1;
BA_ "VFrameFormat" BO_ 2482047024 1;
BA_ "VFrameFormat" BO_ 2399481888 1;
CM_ SG_ 2482047496 BatterySensor_LoadCurrent_Candidate_A "UNCONFIRMED_PENDING_TEST: imported from inputs_outputs DBC. Signal was not present in v49 and requires validation.";
CM_ SG_ 2482047496 Battery_Low_SOC_Alarm_Report_Percent "CONFIRMED_CORRECT_DO_NOT_EDIT: D2 raw percent. more battery config.csv reports 10, 15, 20, 30 after the matching config writes.";
CM_ SG_ 2482047496 Battery_Low_Voltage_Alarm_Report_V "CONFIRMED_CORRECT_DO_NOT_EDIT: D3-D4 little-endian millivolts, scale 0.001 V/count. more battery config.csv reports 10.0, 11.0, 11.5, 12.0 V after the matching config writes.";
BA_ "Decode_Status" BO_ 2482047496 "PARTLY_CONFIRMED";
BA_ "Decode_Status" SG_ 2482047496 BatterySensor_LoadCurrent_Candidate_A "UNCONFIRMED_PENDING_TEST";
BA_ "Decode_Status" SG_ 2482047496 Battery_Low_SOC_Alarm_Report_Percent "CONFIRMED_CORRECT_DO_NOT_EDIT";
BA_ "Decode_Status" SG_ 2482047496 Battery_Low_Voltage_Alarm_Report_V "CONFIRMED_CORRECT_DO_NOT_EDIT";

CM_ "v51 update: merged latest reverse-engineering results from ESPHome/log work: Manager30 solar Wh confirmed as 0x03FCD601 D1=0x00 D2-D5 uint32 Wh; Rouge 1BFD1230 level feedback corrected to base-channel grouped byte layout; Rouge 1BFD1430 identified as hardware button/dimming-active status; Rouge 1BFD0030 documented as coarse status; TVMS1280 1BFD0024 documented as output feedback; module input voltage frames 13F10830/13F10824 added.";
CM_ "v52 update: TVMS1280 hardware has 3 digital inputs. They are currently unused in this installation and no confirmed CAN PGN/byte decode has been identified. Do not confuse them with TVMS Rouge hardware button/dimming-active status 0x1BFD1430. Candidate TVMS1280 status/input frames to test: 0x1BFD0224, 0x1BFCF024, 0x1BFCF224, 0x13F10824.";

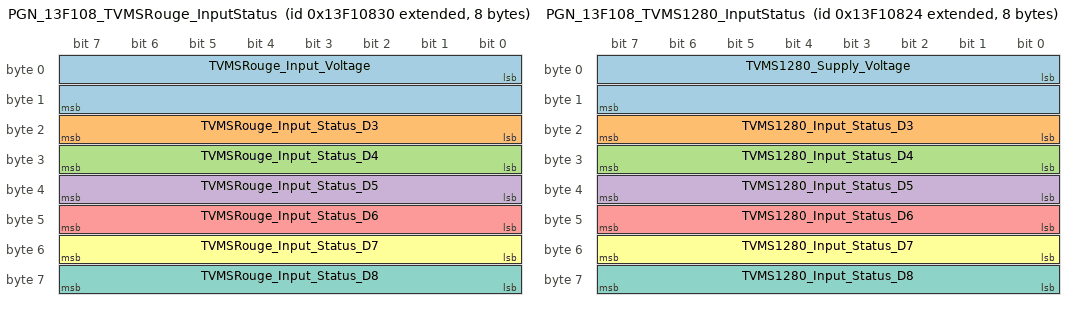
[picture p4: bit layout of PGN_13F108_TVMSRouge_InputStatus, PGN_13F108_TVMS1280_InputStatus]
BO_ 2482047024 PGN_13F108_TVMSRouge_InputStatus: 8 TVMS_Rouge
 SG_ TVMSRouge_Input_Voltage : 0|16@1+ (0.01,0) [0|60] "V" Vector__XXX
 SG_ TVMSRouge_Input_Status_D3 : 16|8@1+ (1,0) [0|255] "raw" Vector__XXX
 SG_ TVMSRouge_Input_Status_D4 : 24|8@1+ (1,0) [0|255] "raw" Vector__XXX
 SG_ TVMSRouge_Input_Status_D5 : 32|8@1+ (1,0) [0|255] "raw" Vector__XXX
 SG_ TVMSRouge_Input_Status_D6 : 40|8@1+ (1,0) [0|255] "raw" Vector__XXX
 SG_ TVMSRouge_Input_Status_D7 : 48|8@1+ (1,0) [0|255] "raw" Vector__XXX
 SG_ TVMSRouge_Input_Status_D8 : 56|8@1+ (1,0) [0|255] "raw" Vector__XXX
CM_ BO_ 2482047024 "CONFIRMED_CORRECT_DO_NOT_EDIT: TVMS Rouge input/status frame. Raw CAN ID 0x13F10830, PGN 0x13F108, SA 0x30.";
CM_ SG_ 2482047024 TVMSRouge_Input_Voltage "SUPERSEDED: Static frame — payload is fixed and does not track live voltage. Live voltage is in 0x1BFD0230 MUX 0x16 D2-D3 LE uint16 millivolts. D1-D2 little-endian, scale 0.01 V/count. Example F0 04 = 12.64 V; EC 04 = 12.60 V.";
BA_ "Decode_Status" BO_ 2482047024 "CONFIRMED_CORRECT_DO_NOT_EDIT";
BA_ "Decode_Status" SG_ 2482047024 TVMSRouge_Input_Voltage "SUPERSEDED";
BA_ "Decode_Status" SG_ 2482047024 TVMSRouge_Input_Status_D3 "UNCONFIRMED_PENDING_TEST";
BA_ "Decode_Status" SG_ 2482047024 TVMSRouge_Input_Status_D4 "UNCONFIRMED_PENDING_TEST";
BA_ "Decode_Status" SG_ 2482047024 TVMSRouge_Input_Status_D5 "UNCONFIRMED_PENDING_TEST";
BA_ "Decode_Status" SG_ 2482047024 TVMSRouge_Input_Status_D6 "UNCONFIRMED_PENDING_TEST";
BA_ "Decode_Status" SG_ 2482047024 TVMSRouge_Input_Status_D7 "UNCONFIRMED_PENDING_TEST";
BA_ "Decode_Status" SG_ 2482047024 TVMSRouge_Input_Status_D8 "UNCONFIRMED_PENDING_TEST";

BO_ 2482047012 PGN_13F108_TVMS1280_InputStatus: 8 TVMS_1280
 SG_ TVMS1280_Supply_Voltage : 0|16@1+ (0.01,0) [0|60] "V" Vector__XXX
 SG_ TVMS1280_Input_Status_D3 : 16|8@1+ (1,0) [0|255] "raw" Vector__XXX
 SG_ TVMS1280_Input_Status_D4 : 24|8@1+ (1,0) [0|255] "raw" Vector__XXX
 SG_ TVMS1280_Input_Status_D5 : 32|8@1+ (1,0) [0|255] "raw" Vector__XXX
 SG_ TVMS1280_Input_Status_D6 : 40|8@1+ (1,0) [0|255] "raw" Vector__XXX
 SG_ TVMS1280_Input_Status_D7 : 48|8@1+ (1,0) [0|255] "raw" Vector__XXX
 SG_ TVMS1280_Input_Status_D8 : 56|8@1+ (1,0) [0|255] "raw" Vector__XXX
CM_ BO_ 2482047012 "PARTLY_CONFIRMED: TVMS1280 input/status frame. Raw CAN ID 0x13F10824, PGN 0x13F108, SA 0x24. Candidate frame to observe while testing the 3 unused TVMS1280 digital inputs. Supply voltage decode moved to PGN 0x1FD02 mux 0x11; D1-D2 here is a static frame value and not a live reading.";
CM_ SG_ 2482047012 TVMS1280_Supply_Voltage "DECODE_WRONG: Frame 0x13F10824 sends static data in every capture (payload never changes). D1-D2 gave a plausible value in early logs but is NOT a live voltage. Supply voltage moved to PGN 0x1FD02 mux 0x11 D4-D5 LE millivolts. See TVMS1280_Supply_Voltage in PGN_1BFD02_TVMS1280_TempTankStatus.";
BA_ "Decode_Status" BO_ 2482047012 "PARTLY_CONFIRMED";
BA_ "Decode_Status" SG_ 2482047012 TVMS1280_Supply_Voltage "DECODE_WRONG";
BA_ "Decode_Status" SG_ 2482047012 TVMS1280_Input_Status_D3 "UNCONFIRMED_PENDING_TEST";
BA_ "Decode_Status" SG_ 2482047012 TVMS1280_Input_Status_D4 "UNCONFIRMED_PENDING_TEST";
BA_ "Decode_Status" SG_ 2482047012 TVMS1280_Input_Status_D5 "UNCONFIRMED_PENDING_TEST";
BA_ "Decode_Status" SG_ 2482047012 TVMS1280_Input_Status_D6 "UNCONFIRMED_PENDING_TEST";
BA_ "Decode_Status" SG_ 2482047012 TVMS1280_Input_Status_D7 "UNCONFIRMED_PENDING_TEST";
BA_ "Decode_Status" SG_ 2482047012 TVMS1280_Input_Status_D8 "UNCONFIRMED_PENDING_TEST";

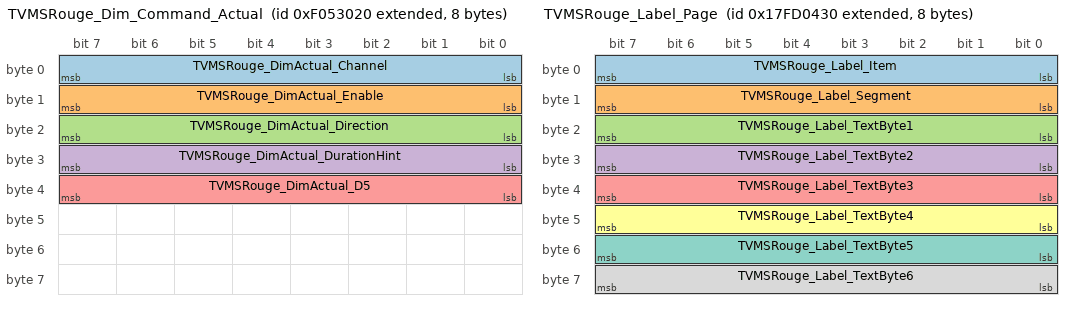
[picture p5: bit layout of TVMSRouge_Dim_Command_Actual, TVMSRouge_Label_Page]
BO_ 2399481888 TVMSRouge_Dim_Command_Actual: 8 Redvision_1
 SG_ TVMSRouge_DimActual_Channel : 0|8@1+ (1,0) [0|255] "channel" Vector__XXX
 SG_ TVMSRouge_DimActual_Enable : 8|8@1+ (1,0) [0|255] "raw" Vector__XXX
 SG_ TVMSRouge_DimActual_Direction : 16|8@1+ (1,0) [0|255] "raw" Vector__XXX
 SG_ TVMSRouge_DimActual_DurationHint : 24|8@1+ (1,0) [0|255] "raw" Vector__XXX
 SG_ TVMSRouge_DimActual_D5 : 32|8@1+ (1,0) [0|255] "raw" Vector__XXX
CM_ BO_ 2399481888 "CONFIRMED_CORRECT_DO_NOT_EDIT: actual TVMS Rouge dim command used by RedVision/ESPHome. Raw CAN ID 0x0F053020. Pattern: <channel> 01 <01 down / 64 up> 05 00 FF FF FF; release is <channel> 01 FF 00 00 FF FF FF.";
CM_ SG_ 2399481888 TVMSRouge_DimActual_Channel "Rouge output channel 0x0C-0x15.";
CM_ SG_ 2399481888 TVMSRouge_DimActual_Direction "0x01=dim down, 0x64=dim up, 0xFF=release.";
VAL_ 2399481888 TVMSRouge_DimActual_Direction 1 "DimDown" 100 "DimUp" 255 "Release";
BA_ "Decode_Status" BO_ 2399481888 "CONFIRMED_CORRECT_DO_NOT_EDIT";
BA_ "Decode_Status" SG_ 2399481888 TVMSRouge_DimActual_Channel "CONFIRMED_CORRECT_DO_NOT_EDIT";
BA_ "Decode_Status" SG_ 2399481888 TVMSRouge_DimActual_Enable "CONFIRMED_CORRECT_DO_NOT_EDIT";
BA_ "Decode_Status" SG_ 2399481888 TVMSRouge_DimActual_Direction "CONFIRMED_CORRECT_DO_NOT_EDIT";
BA_ "Decode_Status" SG_ 2399481888 TVMSRouge_DimActual_DurationHint "CONFIRMED_CORRECT_DO_NOT_EDIT";
BA_ "Decode_Status" SG_ 2399481888 TVMSRouge_DimActual_D5 "CONFIRMED_CORRECT_DO_NOT_EDIT";

BO_ 2549941296 TVMSRouge_Label_Page: 8 TVMS_Rouge
 SG_ TVMSRouge_Label_Item : 0|8@1+ (1,0) [0|255] "item" Vector__XXX
 SG_ TVMSRouge_Label_Segment : 8|8@1+ (1,0) [0|255] "segment" Vector__XXX
 SG_ TVMSRouge_Label_TextByte1 : 16|8@1+ (1,0) [0|255] "ascii" Vector__XXX
 SG_ TVMSRouge_Label_TextByte2 : 24|8@1+ (1,0) [0|255] "ascii" Vector__XXX
 SG_ TVMSRouge_Label_TextByte3 : 32|8@1+ (1,0) [0|255] "ascii" Vector__XXX
 SG_ TVMSRouge_Label_TextByte4 : 40|8@1+ (1,0) [0|255] "ascii" Vector__XXX
 SG_ TVMSRouge_Label_TextByte5 : 48|8@1+ (1,0) [0|255] "ascii" Vector__XXX
 SG_ TVMSRouge_Label_TextByte6 : 56|8@1+ (1,0) [0|255] "ascii" Vector__XXX
CM_ BO_ 2549941296 "CONFIRMED_CORRECT_DO_NOT_EDIT: TVMS Rouge label/name page. Raw CAN ID 0x17FD0430, PGN 0x17FD04, SA 0x30. D1=item id, D2=string segment, D3-D8=ASCII text bytes; 0xFF pads unused text bytes.";
CM_ SG_ 2549941296 TVMSRouge_Label_Item "CONFIRMED_CORRECT_DO_NOT_EDIT: Label item id. Config log confirms item 0x16 = InputVoltage and item 0x17 = InputCurrent.";
CM_ SG_ 2549941296 TVMSRouge_Label_Segment "String segment index. Concatenate D3-D8 ASCII chunks ordered by D2 for the same item id.";
VAL_ 2549941296 TVMSRouge_Label_Item 22 "InputVoltage" 23 "InputCurrent" ;
BA_ "Decode_Status" BO_ 2549941296 "CONFIRMED_CORRECT_DO_NOT_EDIT";
BA_ "Decode_Status" SG_ 2549941296 TVMSRouge_Label_Item "CONFIRMED_CORRECT_DO_NOT_EDIT";
BA_ "Decode_Status" SG_ 2549941296 TVMSRouge_Label_Segment "CONFIRMED_CORRECT_DO_NOT_EDIT";
BA_ "VFrameFormat" BO_ 2549941296 1;

CM_ "v54 update: Added explicit TVMS Rouge label-page decode for raw CAN ID 0x17FD0430. Label item 0x17 is InputCurrent. Later review shows this does not support the 0x1BFD0230 D1=0x16 D3/10 A candidate because D3 is part of input voltage.";
CM_ "v56 update: Added confirmed Battery Sensor configured-capacity decode. Config write raw CAN ID 0x0F0008FA uses D5-D6 little-endian Ah; status echo raw CAN ID 0x13F10008 uses D2-D3 little-endian Ah. Confirmed from battery 450ah - 350 - 400.csv sequence 450, 400, 350, 400 Ah.";
CM_ "v57 update: Added confirmed Battery Sensor max charge current decode. Config write raw CAN ID 0x0F0008FA with D1=0x14 uses D5-D6 little-endian A; status echo raw CAN ID 0x13F10008 uses D5 raw A. Confirmed corrected sequence 20, 14, 10, 30 A.";
CM_ "v58 update: Added confirmed Battery Sensor alarm config writes. Raw CAN ID 0x0F0008FA D1=0x41 uses D5-D6 little-endian percent for low SOC alarm; D1=0x42 uses D5-D6 little-endian millivolts for low voltage alarm. Confirmed sequences 10,15,20,30% and 10.0,11.0,11.5,12.0 V.";
CM_ "v72 decode model: TVMS status DGNs commonly use D1 as the base item/channel ID. For byte-state pages D2-D8 map to base..base+6. For analog pages, each item may consume multiple bytes, so the next byte is not automatically the next item. Example: Rouge item 0x16 InputVoltage uses D2-D3 little-endian millivolts; D3 must not be decoded as item 0x17 InputCurrent.";
CM_ "v73 update: Manager30 solar generation history on raw CAN ID 0x03FCD601 / DGN 0x1FCD6 is paged daily Wh data, not one 32-bit counter. D1=page index. D2-D3, D4-D5 and D6-D7 are little-endian Wh buckets. Page 0 = today, day-1, day-2; page 1 = day-3, day-4, day-5; page 2 = day-6, day-7, unused. Example from solar per day.csv: 45,208,26,1,149,406,397,402 Wh sum to 1634 Wh.";
CM_ "v74 update: Added conservative CAN status/heartbeat abnormal monitor in ESPHome. It watches known repeated status frames and reports HA abnormal only for confirmed suspicious values: unknown Manager30 charging-stage byte, invalid Manager30 vehicle-trigger byte, short CAN payloads, or unexpected byte values on TVMS byte-state pages. Unknown private DGNs are not treated as abnormal.";
CM_ "v75 update: solar WH.csv confirms Manager30 solar history pages 0x03FCD601 are emitted after request raw CAN ID 0x0FFCD6FA with all-zero payload. ESPHome now periodically sends 0x0FFCD6FA to refresh Solar Today and the 8-day history without needing the RedVision screen/app to open the solar history page.";
CM_ "v76 update: SOC log.csv confirms Battery Sensor SOC history. Request 0x0FFCD0FA returns hourly SOC on 0x13FCD008 pages D1=0..3, D2-D8 sequential percent values. Request 0x0FFCD2FA returns daily low/min SOC on 0x13FCD208 pages D1=0..4. Request 0x0FFCD4FA returns daily high/max SOC on 0x13FCD408 pages D1=0..4. D2-D8 are sequential percent values; 0xFF is no data.";
CM_ "v77 update: ESPHome also publishes Manager30 solar generation day -1 through day -5 as one compact HA text sensor. Values remain sourced from DGN 0x1FCD6 pages; text order is day-1,day-2,day-3,day-4,day-5 in Wh, with 255 used for an unknown slot.";
CM_ "v59 update: Added confirmed Battery Sensor alarm report fields on raw CAN ID 0x13F10A08. D2 reports low SOC alarm percent; D3-D4 little-endian millivolts report low voltage alarm. Confirmed around write transitions in more battery config.csv.";
CM_ "v60 update: Added confirmed Battery Sensor SOC calibration target command. Raw CAN ID 0x0F0008FA D1=0x15 uses D5-D6 little-endian percent; calibrate battery start of charge full 5 times.csv captured five repeats of 100%.";
CM_ "v61 update: Added confirmed Battery Sensor battery type decode. Config write raw CAN ID 0x0F0008FA D1=0x11 uses D5-D6 little-endian type; status raw CAN ID 0x13F10008 D1 reports type. Mapping: 0=Gel, 1=AGM, 2=LeadAcid, 3=Calcium, 4=Lithium.";
CM_ "v62 update: Added confirmed Manager30 vehicle input trigger decode. Config write raw CAN ID 0x0F0001FA uses D1=0x68, D3=0x03, D5-D6 little-endian trigger; status raw CAN ID 0x03F20601 reports trigger in D8. Mapping: 0=Auto, 1=12V, 2=24V, 3=Ignition, 5=On.";
CM_ "v63 update: Added confirmed Redvision Display setting-change broadcast decode. Raw CAN ID 0x0F00FF20 from source 0x20 uses D1 as setting ID and D5-D6 little-endian value for battery type, capacity, max charge current, low SOC alarm, low voltage alarm, and vehicle input trigger.";
CM_ "v64 update: Added unconfirmed TVMS master command entries based on config/label pages: TVMS1280 item/channel 0x0F is Master switch, TVMS Rouge item/channel 0x0B is Master. ESPHome exposes them as HA switches using the existing TVMS on/off command shape.";
CM_ "v65 update: Added ESPHome test entities for TVMS1280 digital inputs 1-3. Channel map supplied by user: digital inputs are 0x01-0x03, outputs are 0x04-0x0D, inverter is 0x0E, master is 0x0F. Live-state PGN is still candidate; current test path uses 0x1BFD0024 channel feedback.";
CM_ "v66 update: Confirmed TVMS Rouge physical input/button states on 0x1BFD0030. D1=0x01 maps D2-D8 to inputs/buttons 1-7; D1=0x08 maps D2 to input/button 8. State values: 0x00 inactive, 0x01 active. 0x1BFD1430 remained idle in this test and is retained only as output/dimming activity status.";
CM_ "v67 update: Added Manager30 charging mode and charging stage decode. RedVision 0x0F00FF20 D1=0x43 D5 sets mode: 0=Touring, 1=Storage. Manager30 0x03F10801 D1 bit0 confirms mode. Manager30 0x03F20001 D1 reports stage: 0x00/0x01=Not Charging, 0x21=Soft-start, 0x30/0x31=Boost, 0x40/0x41=Absorption, 0x70/0x71=Float, 0x80/0x81=Maintenance; low bit 1 means Storage mode. 0x4D remains a charge-cycle/stage request candidate.";

CM_ SG_ 2617049636 TVMS1280_Temp2_C "NOTE: TVMS1280 voltage inputs are item/channel 0x11 and 0x12 within the 0x1BFD0224 mux 0x11 page. Voltage Input 1 is D2-D3 millivolts, Voltage Input 2 is D4-D5 millivolts.";
CM_ SG_ 2617049636 TVMS1280_Temp1_C "NOTE: Temp1 is MUX 0x14 D2. Voltage Input 2 is not on this page; it is item/channel 0x12 in MUX 0x11 D4-D5 millivolts.";

CM_ "TVMS1280_DIGITAL_INPUTS_NOTE: Hardware has 3 digital inputs mapped to channels 0x01, 0x02, and 0x03. ESPHome exposes candidate binary sensors from 0x1BFD0024 channel feedback for field testing. A one-at-a-time input toggle capture is still needed before marking the live-state decode confirmed.";
